VERSION ""

NS_ :

BS_:

BU_: IBCMR GW LAS AS

BO_ 1107 ACC_NM: 8 GW
 SG_ ACC_NMSourceAddress : 7|8@0+ (1,0) [0|255] ""  LAS

BO_ 1030 GW_NM: 8 GW
 SG_ GW_NMSourceAddress : 7|8@0+ (1,0) [0|255] ""  LAS

BO_ 1106 LAS_NM: 8 LAS
 SG_ LAS_NMSourceAddress : 7|8@0+ (1,0) [0|255] "" Vector__XXX

BO_ 676 ADC_2A4: 64 GW
 SG_ LCDAR_CRCCheck_2AF : 63|8@0+ (1,0) [0|255] ""  LAS
 SG_ LCDAR_RollingCounter_2AF : 51|4@0+ (1,0) [0|15] ""  LAS
 SG_ LCDAR_ELK_oAlert : 25|2@0+ (1,0) [0|3] ""  LAS
 SG_ LCDAR_ELK_oStatus : 27|2@0+ (1,0) [0|3] ""  LAS
 SG_ LCDAR_Left_ELK_oAlert : 29|2@0+ (1,0) [0|3] ""  LAS

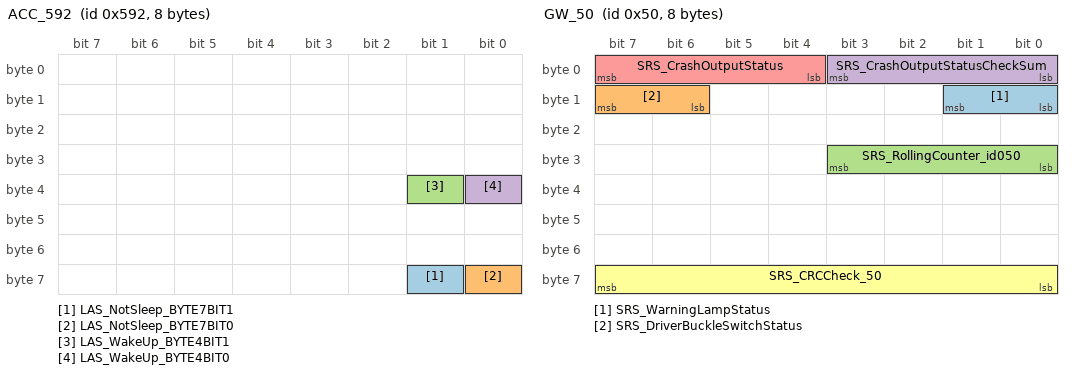
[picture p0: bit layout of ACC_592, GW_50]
BO_ 1426 ACC_592: 8 GW
 SG_ LAS_NotSleep_BYTE7BIT1 : 57|1@0+ (1,0) [0|1] ""  LAS
 SG_ LAS_NotSleep_BYTE7BIT0 : 56|1@0+ (1,0) [0|1] ""  LAS
 SG_ LAS_WakeUp_BYTE4BIT1 : 33|1@0+ (1,0) [0|1] ""  LAS
 SG_ LAS_WakeUp_BYTE4BIT0 : 32|1@0+ (1,0) [0|1] ""  LAS

BO_ 80 GW_50: 8 GW
 SG_ SRS_WarningLampStatus : 9|2@0+ (1,0) [0|3] ""  LAS
 SG_ SRS_DriverBuckleSwitchStatus : 15|2@0+ (1,0) [0|3] ""  LAS
 SG_ SRS_RollingCounter_id050 : 27|4@0+ (1,0) [0|15] ""  LAS
 SG_ SRS_CrashOutputStatusCheckSum : 3|4@0+ (1,0) [0|15] ""  LAS
 SG_ SRS_CrashOutputStatus : 7|4@0+ (1,0) [0|15] ""  LAS
 SG_ SRS_CRCCheck_50 : 63|8@0+ (1,0) [0|255] ""  LAS

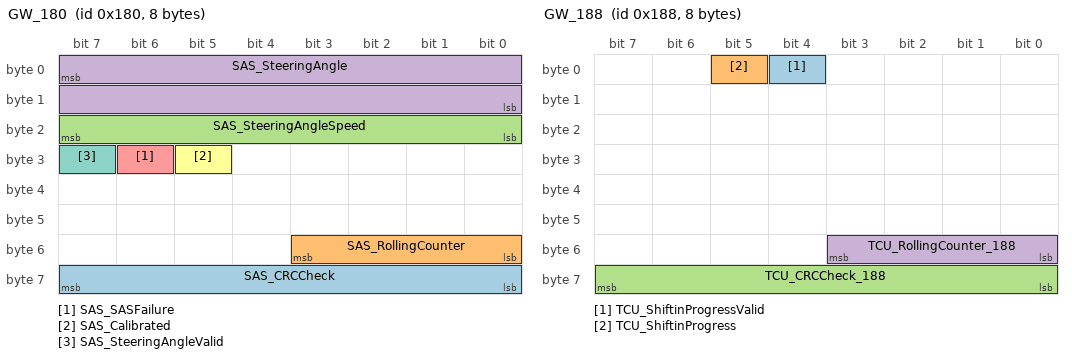
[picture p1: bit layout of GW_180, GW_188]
BO_ 384 GW_180: 8 GW
 SG_ SAS_CRCCheck : 63|8@0+ (1,0) [0|255] ""  LAS
 SG_ SAS_RollingCounter : 51|4@0+ (1,0) [0|15] ""  LAS
 SG_ SAS_SteeringAngleSpeed : 23|8@0+ (4,0) [0|1016] "deg/s"  LAS
 SG_ SAS_SteeringAngle : 7|16@0- (0.1,0) [-780|780] "degree"  LAS
 SG_ SAS_SASFailure : 30|1@0+ (1,0) [0|1] ""  LAS
 SG_ SAS_Calibrated : 29|1@0+ (1,0) [0|1] ""  LAS
 SG_ SAS_SteeringAngleValid : 31|1@0+ (1,0) [0|1] ""  LAS

BO_ 392 GW_188: 8 GW
 SG_ TCU_ShiftinProgressValid : 4|1@0+ (1,0) [0|1] ""  LAS
 SG_ TCU_ShiftinProgress : 5|1@0+ (1,0) [0|1] ""  LAS
 SG_ TCU_CRCCheck_188 : 63|8@0+ (1,0) [0|255] ""  LAS
 SG_ TCU_RollingCounter_188 : 51|4@0+ (1,0) [0|15] ""  LAS

BO_ 580 ADS_244: 64 GW
 SG_ ACC_AEBActive : 87|1@0+ (1,0) [0|1] ""  LAS

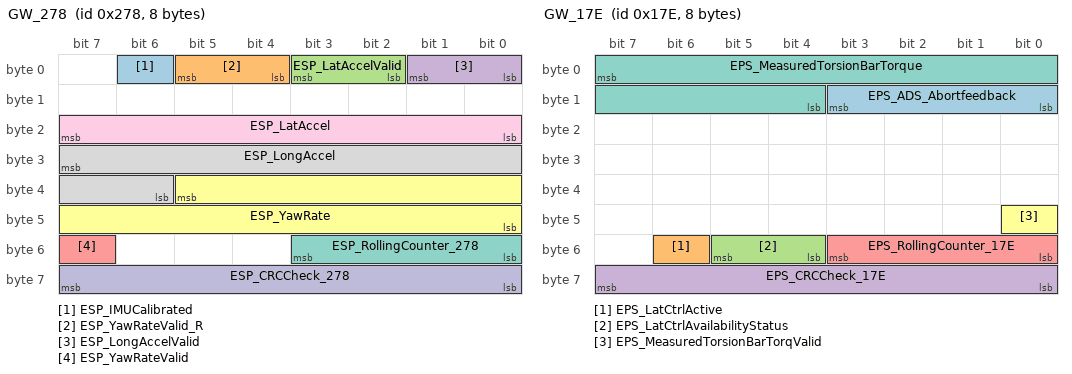
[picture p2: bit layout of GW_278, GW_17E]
BO_ 632 GW_278: 8 GW
 SG_ ESP_IMUCalibrated : 6|1@0+ (1,0) [0|1] ""  LAS
 SG_ ESP_YawRateValid_R : 5|2@0+ (1,0) [0|3] ""  LAS
 SG_ ESP_LatAccelValid : 3|2@0+ (1,0) [0|3] ""  LAS
 SG_ ESP_LongAccelValid : 1|2@0+ (1,0) [0|3] ""  LAS
 SG_ ESP_YawRateValid : 55|1@0+ (1,0) [0|1] ""  LAS
 SG_ ESP_YawRate : 37|14@0+ (0.01,-81.91) [-81.91|81.91] "degree/s"  LAS
 SG_ ESP_RollingCounter_278 : 51|4@0+ (1,0) [0|15] ""  LAS
 SG_ ESP_LongAccel : 31|10@0+ (0.03125,-16) [-16|15.90625] "m/s2"  LAS
 SG_ ESP_LatAccel : 23|8@0+ (0.1,-12.7) [-12.7|12.7] "m/s2"  LAS
 SG_ ESP_CRCCheck_278 : 63|8@0+ (1,0) [0|255] ""  LAS

BO_ 664 GW_298: 8 GW
 SG_ BCM_LeftRearDoorStatus : 40|1@0+ (1,0) [0|1] ""  LAS

BO_ 832 IBCMR_340: 8 IBCMR
 SG_ AC_FrBlowType : 2|3@0+ (1,0) [0|7] ""  LAS

BO_ 870 IBCMR_366: 8 IBCMR
 SG_ AC_EnvironmentalTemp : 23|8@0+ (0.5,-40) [-40|87] "degreeC"  LAS
 SG_ AC_EnvironmentalTempVD : 8|1@0+ (1,0) [0|1] ""  LAS

BO_ 903 GW_387: 8 GW
 SG_ BCM_RainfallLevel : 19|4@0+ (1,0) [0|15] ""  LAS
 SG_ BCM_FrontWiperStatus : 25|2@0+ (1,0) [0|3] ""  LAS

BO_ 1287 GW_507: 64 GW
 SG_ HU_FCWSetting : 165|3@0+ (1,0) [0|7] ""  LAS
 SG_ HU_IACCEnable : 29|2@0+ (1,0) [0|3] ""  LAS
 SG_ HU_LDWShakeLev : 23|2@0+ (1,0) [0|3] ""  LAS
 SG_ HU_HMAEnable : 12|1@0+ (1,0) [0|1] ""  LAS
 SG_ HU_TSRSwitch : 11|1@0+ (1,0) [0|1] ""  LAS
 SG_ HU_LASWarningModeSelection : 10|3@0+ (1,0) [0|7] ""  LAS
 SG_ HU_LASModeSelection : 5|3@0+ (1,0) [0|7] ""  LAS
 SG_ HU_OverspeedWarningOffset : 38|5@0+ (1,-10) [-10|10] ""  LAS
 SG_ HU_OverspeedWarningEnable : 33|2@0+ (1,0) [0|3] ""  LAS
 SG_ HU_OverspeedSoundWarEnable : 31|2@0+ (1,0) [0|3] ""  LAS

BO_ 1302 GW_516: 32 GW
 SG_ HU_LocalTimeSystem : 111|2@0+ (1,0) [0|3] ""  LAS
 SG_ HU_LocalTimeSecond : 109|6@0+ (1,0) [0|59] "second"  LAS
 SG_ HU_LocalTimeMinute : 101|6@0+ (1,0) [0|59] "minute"  LAS
 SG_ HU_LocalTimeHour : 92|5@0+ (1,0) [0|23] "hour"  LAS
 SG_ HU_LocalTimeDate : 84|5@0+ (1,0) [1|31] "day"  LAS
 SG_ HU_LocalTimeYear : 119|8@0+ (1,2013) [2013|2268] "year"  LAS
 SG_ HU_LocalTimeMonth : 75|4@0+ (1,0) [1|12] "month"  LAS
 SG_ HU_LocalTimeValid : 71|1@0+ (1,0) [0|1] ""  LAS
 SG_ HU_CurrentLocationLatitude : 35|28@0+ (1E-006,-134.217727) [-90|90] "degree"  LAS
 SG_ HU_CurrentLocationLongitude : 4|29@0+ (1E-006,-268.435455) [-180|180] "degree"  LAS
 SG_ HU_CurrentLocationValid : 7|1@0+ (1,0) [0|1] ""  LAS

BO_ 1328 GW_530: 8 GW
 SG_ IP_TotalOdometer : 23|24@0+ (0.1,0) [0|999999] "Km"  LAS

BO_ 378 GW_17A: 64 GW
 SG_ ESP_VehicleSpeed : 36|13@0+ (0.05625,0) [0|360] "km/h"  LAS
 SG_ ESP_VehicleSpeedValid : 37|1@0+ (1,0) [0|1] ""  LAS
 SG_ ESP_TCSFailStatus : 4|1@0+ (1,0) [0|1] ""  LAS
 SG_ ESP_RollingCounter_187 : 51|4@0+ (1,0) [0|15] ""  LAS
 SG_ ESP_ESPFunctionStatus : 1|1@0+ (1,0) [0|1] ""  LAS
 SG_ ESP_ESPActiveStatus : 0|1@0+ (1,0) [0|1] ""  LAS
 SG_ ESP_CRCCheck_197 : 127|8@0+ (1,0) [0|255] ""  LAS
 SG_ ESP_CRCCheck_187 : 63|8@0+ (1,0) [0|255] ""  LAS
 SG_ ESP_ABSFailStatus : 3|1@0+ (1,0) [0|1] ""  LAS
 SG_ ESP_ABSActiveStatus : 7|1@0+ (1,0) [0|1] ""  LAS

BO_ 382 GW_17E: 8 GW
 SG_ EPS_ADS_Abortfeedback : 11|4@0+ (1,0) [0|15] ""  LAS
 SG_ EPS_LatCtrlActive : 54|1@0+ (1,0) [0|1] ""  LAS
 SG_ EPS_LatCtrlAvailabilityStatus : 53|2@0+ (1,0) [0|3] ""  LAS
 SG_ EPS_CRCCheck_17E : 63|8@0+ (1,0) [0|255] ""  LAS
 SG_ EPS_RollingCounter_17E : 51|4@0+ (1,0) [0|15] ""  LAS
 SG_ EPS_MeasuredTorsionBarTorqValid : 40|1@0+ (1,0) [0|1] ""  LAS
 SG_ EPS_MeasuredTorsionBarTorque : 7|12@0+ (0.01,-20.48) [-20.48|20.46] "Nm"  LAS

BO_ 398 GW_18E: 32 GW
 SG_ EMS_CRCCheck_1A6 : 191|8@0+ (1,0) [0|255] ""  LAS
 SG_ EMS_RollingCounter_1A6 : 179|4@0+ (1,0) [0|15] ""  LAS
 SG_ EMS_EngineStatus : 183|2@0+ (1,0) [0|3] ""  LAS
 SG_ EMS_AccPedal : 111|8@0+ (0.392,0) [0|99.568] "%"  LAS
 SG_ EMS_EngineSpeed : 87|16@0+ (0.25,0) [0|16383.5] "Rpm"  LAS
 SG_ EMS_BrakePedalStatus : 119|2@0+ (1,0) [0|3] ""  LAS
 SG_ EMS_RealAccPedal : 71|8@0+ (0.392,0) [0|99.568] "%"  LAS

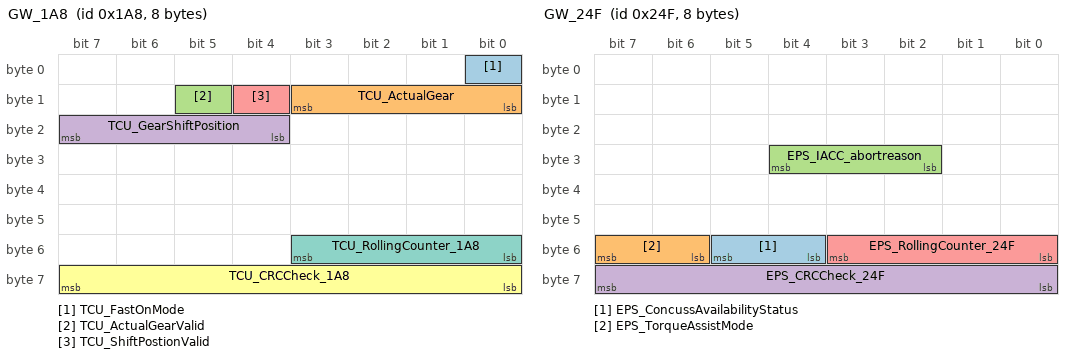
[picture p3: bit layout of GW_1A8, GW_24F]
BO_ 424 GW_1A8: 8 GW
 SG_ TCU_FastOnMode : 0|1@0+ (1,0) [0|1] ""  LAS
 SG_ TCU_ActualGear : 11|4@0+ (1,0) [0|15] ""  LAS
 SG_ TCU_ActualGearValid : 13|1@0+ (1,0) [0|1] ""  LAS
 SG_ TCU_GearShiftPosition : 23|4@0+ (1,0) [0|15] ""  LAS
 SG_ TCU_ShiftPostionValid : 12|1@0+ (1,0) [0|1] ""  LAS
 SG_ TCU_CRCCheck_1A8 : 63|8@0+ (1,0) [0|255] ""  LAS
 SG_ TCU_RollingCounter_1A8 : 51|4@0+ (1,0) [0|15] ""  LAS

BO_ 523 EPBi_20B: 64 GW
 SG_ Wheel_Speed_FL_Pulse : 135|8@0+ (1,0) [0|254] ""  LAS
 SG_ Wheel_Speed_FR_Pulse : 159|8@0+ (1,0) [0|254] ""  LAS
 SG_ ESP_Vehicle_Speed_Reference : 103|13@0+ (0.05625,0) [0|360] "km/h"  LAS
 SG_ Wheel_Speed_RR_Valid_Data : 71|1@0+ (1,0) [0|1] ""  LAS
 SG_ Wheel_Speed_RR_Pulse : 231|8@0+ (1,0) [0|254] ""  LAS
 SG_ Wheel_Speed_RR_Direction : 70|2@0+ (1,0) [0|3] ""  LAS
 SG_ Wheel_Speed_RR_Data : 68|13@0+ (0.05625,0) [0|360] "km/h"  LAS
 SG_ Wheel_Speed_RL_Valid_Data : 87|1@0+ (1,0) [0|1] ""  LAS
 SG_ Wheel_Speed_RL_Pulse : 239|8@0+ (1,0) [0|254] ""  LAS
 SG_ Wheel_Speed_RL_Direction : 86|2@0+ (1,0) [0|3] ""  LAS
 SG_ Wheel_Speed_RL_Data : 84|13@0+ (0.05625,0) [0|360] "km/h"  LAS
 SG_ Wheel_Speed_FR_Valid_Data : 7|1@0+ (1,0) [0|1] ""  LAS
 SG_ Wheel_Speed_FR_Pulse : 223|8@0+ (1,0) [0|254] ""  LAS
 SG_ Wheel_Speed_FR_Direction : 6|2@0+ (1,0) [0|3] ""  LAS
 SG_ Wheel_Speed_FR_Data : 4|13@0+ (0.05625,0) [0|360] "km/h"  LAS
 SG_ Wheel_Speed_FL_Valid_Data : 23|1@0+ (1,0) [0|1] ""  LAS
 SG_ Wheel_Speed_FL_Pulse : 215|8@0+ (1,0) [0|254] ""  LAS
 SG_ Wheel_Speed_FL_Direction : 22|2@0+ (1,0) [0|3] ""  LAS
 SG_ Wheel_Speed_FL_Data : 20|13@0+ (0.05625,0) [0|360] "km/h"  LAS
 SG_ ESP_VehicleStandstill : 267|1@0+ (1,0) [0|1] ""  LAS
 SG_ ESP_VDCActive : 266|1@0+ (1,0) [0|1] ""  LAS
 SG_ ESP_TCSActive : 265|1@0+ (1,0) [0|1] ""  LAS
 SG_ ESP_RollingCounter_277 : 307|4@0+ (1,0) [0|15] ""  LAS
 SG_ ESP_RollingCounter_258 : 243|4@0+ (1,0) [0|15] ""  LAS
 SG_ ESP_RollingCounter_208 : 115|4@0+ (1,0) [0|15] ""  LAS
 SG_ ESP_RollingCounter_206 : 51|4@0+ (1,0) [0|15] ""  LAS
 SG_ ESP_PrefillAvailable : 259|1@0+ (1,0) [0|1] ""  LAS
 SG_ ESP_PrefillActive : 260|1@0+ (1,0) [0|1] ""  LAS
 SG_ ESP_OnlyABSActive : 264|1@0+ (1,0) [0|1] ""  LAS
 SG_ ESP_MasCylBrakePressureValid : 199|1@0+ (1,0) [0|1] ""  LAS
 SG_ ESP_MasCylBrakePressure : 195|12@0+ (0.1,0) [0|250] "Bar"  LAS
 SG_ ESP_CRCCheck_277 : 319|8@0+ (1,0) [0|255] ""  LAS
 SG_ ESP_CRCCheck_258 : 255|8@0+ (1,0) [0|255] ""  LAS
 SG_ ESP_CRCCheck_208 : 127|8@0+ (1,0) [0|255] ""  LAS
 SG_ ESP_CRCCheck_206 : 63|8@0+ (1,0) [0|255] ""  LAS
 SG_ ESP_BrakeForce : 263|1@0+ (1,0) [0|1] ""  LAS
 SG_ ESP_AWBavailable : 271|1@0+ (1,0) [0|1] ""  LAS
 SG_ ESP_AWBactive : 256|1@0+ (1,0) [0|1] ""  LAS
 SG_ ESP_AEBdecActive : 257|1@0+ (1,0) [0|1] ""  LAS
 SG_ ESP_AEBAvailable : 258|1@0+ (1,0) [0|1] ""  LAS
 SG_ ESP_ABAavailable : 261|1@0+ (1,0) [0|1] ""  LAS
 SG_ ESP_ABAactive : 262|1@0+ (1,0) [0|1] ""  LAS

BO_ 591 GW_24F: 8 GW
 SG_ EPS_ConcussAvailabilityStatus : 53|2@0+ (1,0) [0|3] ""  LAS
 SG_ EPS_TorqueAssistMode : 55|2@0+ (1,0) [0|3] ""  LAS
 SG_ EPS_IACC_abortreason : 28|3@0+ (1,0) [0|7] ""  LAS
 SG_ EPS_CRCCheck_24F : 63|8@0+ (1,0) [0|255] ""  LAS
 SG_ EPS_RollingCounter_24F : 51|4@0+ (1,0) [0|15] ""  LAS

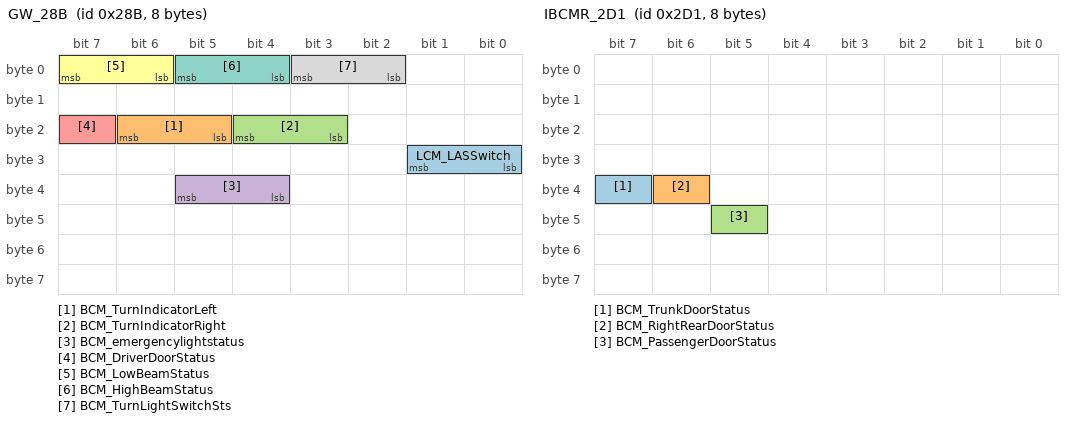
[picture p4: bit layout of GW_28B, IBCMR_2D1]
BO_ 651 GW_28B: 8 GW
 SG_ LCM_LASSwitch : 25|2@0+ (1,0) [0|3] ""  LAS
 SG_ BCM_TurnIndicatorLeft : 22|2@0+ (1,0) [0|3] ""  LAS
 SG_ BCM_TurnIndicatorRight : 20|2@0+ (1,0) [0|3] ""  LAS
 SG_ BCM_emergencylightstatus : 37|2@0+ (1,0) [0|3] ""  LAS
 SG_ BCM_DriverDoorStatus : 23|1@0+ (1,0) [0|1] ""  LAS
 SG_ BCM_LowBeamStatus : 7|2@0+ (1,0) [0|3] ""  LAS
 SG_ BCM_HighBeamStatus : 5|2@0+ (1,0) [0|3] ""  LAS
 SG_ BCM_TurnLightSwitchSts : 3|2@0+ (1,0) [0|3] ""  LAS

BO_ 721 IBCMR_2D1: 8 IBCMR
 SG_ BCM_TrunkDoorStatus : 39|1@0+ (1,0) [0|1] ""  LAS
 SG_ BCM_RightRearDoorStatus : 38|1@0+ (1,0) [0|1] ""  LAS
 SG_ BCM_PassengerDoorStatus : 45|1@0+ (1,0) [0|1] ""  LAS

BO_ 943 GW_3AF: 64 GW
 SG_ HU_CRCCheck_3AF : 255|8@0+ (1,0) [0|255] ""  LAS
 SG_ HU_RollingCounter_3AF : 243|4@0+ (1,0) [0|15] ""  LAS
 SG_ HU_RampDistance : 239|10@0+ (10,0) [0|3000] "m"  LAS
 SG_ HU_NavSpeedLimitType : 231|2@0+ (1,0) [0|3] ""  LAS
 SG_ HU_CurveDistance : 229|6@0+ (10,0) [0|600] "m"  LAS
 SG_ HU_EnterCurveInfo : 220|2@0+ (1,0) [0|3] ""  LAS
 SG_ HU_NavCurrentRoadType : 218|3@0+ (1,0) [0|7] ""  LAS
 SG_ HU_EnterRampInfo : 215|2@0+ (1,0) [0|3] ""  LAS
 SG_ HU_RampInfo : 209|2@0+ (1,0) [0|3] ""  LAS
 SG_ HU_NavCountryCode : 199|8@0+ (1,0) [0|255] ""  LAS
 SG_ HU_NavStatus : 223|1@0+ (1,0) [0|1] ""  LAS
 SG_ HU_NavSpeedLimitUnits : 213|2@0+ (1,0) [0|3] ""  LAS
 SG_ HU_NavSpeedLimitStatus : 211|2@0+ (1,0) [0|3] ""  LAS
 SG_ HU_NavSpeedLimit : 207|8@0+ (1,0) [0|255] ""  LAS

BO_ 947 IBCMR_3B3: 8 IBCMR
 SG_ BCM_RearFoglampStatus : 19|2@0+ (1,0) [0|3] ""  LAS

BO_ 957 GW_3BD: 64 GW
 SG_ HU_ELKEnable : 1|2@0+ (1,0) [0|3] ""  LAS
 SG_ HU_TLAEnable : 9|2@0+ (1,0) [0|3] ""  LAS

BO_ 964 GW_3C4: 64 GW
 SG_ HU_CRCCheck_3C7 : 319|8@0+ (1,0) [0|255] ""  LAS
 SG_ HU_RollingCounter_3C7 : 307|4@0+ (1,0) [0|15] ""  LAS
 SG_ HU_CRCCheck_3C6 : 255|8@0+ (1,0) [0|255] ""  LAS
 SG_ HU_RollingCounter_3C6 : 243|4@0+ (1,0) [0|15] ""  LAS
 SG_ HU_CRCCheck_3C4 : 191|8@0+ (1,0) [0|255] ""  LAS
 SG_ HU_RollingCounter_3C4 : 179|4@0+ (1,0) [0|15] ""  LAS
 SG_ HU_CRCCheck_3C2 : 127|8@0+ (1,0) [0|255] ""  LAS
 SG_ HU_RollingCounter_3C2 : 115|4@0+ (1,0) [0|15] ""  LAS
 SG_ HU_MapMatchStatus : 309|2@0+ (1,0) [0|3] ""  LAS
 SG_ HU_MapDataUpdateStatus : 118|3@0+ (1,0) [0|7] ""  LAS
 SG_ HU_SlopeGradient_300m : 303|10@0+ (0.1,-51.1) [-51.1|51.1] "%"  LAS
 SG_ HU_RoadCurvature_600m : 281|10@0+ (1,0) [0|1023] "1/m"  LAS
 SG_ HU_RoadCurvature_400m : 275|10@0+ (1,0) [0|1023] "1/m"  LAS
 SG_ HU_RoadCurvature_300m : 269|10@0+ (1,0) [0|1023] "1/m"  LAS
 SG_ HU_RoadCurvature_100m : 263|10@0+ (1,0) [0|1023] "1/m"  LAS
 SG_ HU_RoadCurvature_90m : 239|10@0+ (1,0) [0|1023] "1/m"  LAS
 SG_ HU_RoadCurvature_80m : 217|10@0+ (1,0) [0|1023] "1/m"  LAS
 SG_ HU_RoadCurvature_70m : 211|10@0+ (1,0) [0|1023] "1/m"  LAS
 SG_ HU_RoadCurvature_60m : 205|10@0+ (1,0) [0|1023] "1/m"  LAS
 SG_ HU_RoadCurvature_50m : 199|10@0+ (1,0) [0|1023] "1/m"  LAS
 SG_ HU_RoadCurvature_40m : 161|10@0+ (1,0) [0|1023] "1/m"  LAS
 SG_ HU_RoadCurvature_30m : 155|10@0+ (1,0) [0|1023] "1/m"  LAS
 SG_ HU_RoadCurvature_20m : 149|10@0+ (1,0) [0|1023] "1/m"  LAS
 SG_ HU_RoadCurvature_10m : 143|10@0+ (1,0) [0|1023] "1/m"  LAS
 SG_ HU_Road_TrafficFlow : 105|3@0+ (1,0) [0|7] ""  LAS
 SG_ HU_Lane_Changtype : 129|2@0+ (1,0) [0|3] ""  LAS
 SG_ HU_To_NumchangeOfLanes_Dist : 135|6@0+ (10,0) [0|600] "m"  LAS
 SG_ HU_To_Branch_Dis : 111|6@0+ (10,0) [0|600] "m"  LAS
 SG_ HU_BranchInfo : 245|2@0+ (1,0) [0|3] ""  LAS
 SG_ HU_To_TrafficAccident_Dis : 101|6@0+ (10,0) [0|600] "m"  LAS
 SG_ HU_TrafficAccident_Info : 103|2@0+ (1,0) [0|3] ""  LAS
 SG_ HU_To_Construction_Dis : 93|6@0+ (10,0) [0|600] "m"  LAS
 SG_ HU_Construction_Info : 95|2@0+ (1,0) [0|3] ""  LAS
 SG_ HU_TollDis : 85|6@0+ (10,0) [0|600] "m"  LAS
 SG_ HU_TollInfo : 87|2@0+ (1,0) [0|3] ""  LAS
 SG_ HU_FallingRockDi : 77|6@0+ (10,0) [0|600] "m"  LAS
 SG_ HU_FallingRockInfo : 79|2@0+ (1,0) [0|3] ""  LAS
 SG_ HU_LaneCnt : 66|3@0+ (1,0) [0|7] ""  LAS
 SG_ HU_ForwardRoadType : 69|3@0+ (1,0) [0|7] ""  LAS
 SG_ HU_RampSide : 71|2@0+ (1,0) [0|3] ""  LAS
 SG_ HU_CRCCheck_3B8 : 63|8@0+ (1,0) [0|255] ""  LAS
 SG_ HU_RollingCounter_3B8 : 51|4@0+ (1,0) [0|15] ""  LAS
 SG_ HU_NavGuiganceStatus : 47|2@0+ (1,0) [0|3] ""  LAS
 SG_ HU_SlopeDistance : 45|6@0+ (10,0) [0|600] "m"  LAS
 SG_ HU_Byroad : 39|2@0+ (1,0) [0|3] ""  LAS
 SG_ HU_TunnelLength : 37|6@0+ (1,0) [0|63] "m"  LAS
 SG_ HU_RoadCurvatureFar : 17|10@0+ (1,0) [0|1023] ""  LAS
 SG_ HU_TunnelDistance : 23|6@0+ (10,0) [0|600] "m"  LAS
 SG_ HU_RoadCurvature : 1|10@0+ (1,0) [0|1023] ""  LAS
 SG_ HU_EnterSlopeInfo : 5|2@0+ (1,0) [0|3] ""  LAS
 SG_ HU_EnterTunnelInfo : 3|2@0+ (1,0) [0|3] ""  LAS

BO_ 1021 GW_3FD: 8 GW
 SG_ BCM_PowerManageLevel : 8|3@0+ (1,0) [0|7] ""  LAS

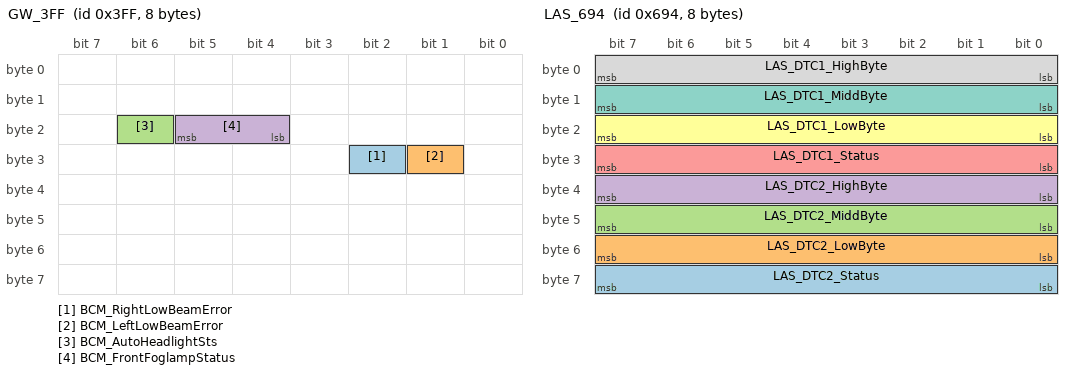
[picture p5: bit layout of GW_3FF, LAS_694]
BO_ 1023 GW_3FF: 8 GW
 SG_ BCM_RightLowBeamError : 26|1@0+ (1,0) [0|1] ""  LAS
 SG_ BCM_LeftLowBeamError : 25|1@0+ (1,0) [0|1] ""  LAS
 SG_ BCM_AutoHeadlightSts : 22|1@0+ (1,0) [0|1] ""  LAS
 SG_ BCM_FrontFoglampStatus : 21|2@0+ (1,0) [0|3] ""  LAS

BO_ 1684 LAS_694: 8 LAS
 SG_ LAS_DTC2_Status : 63|8@0+ (1,0) [0|255] "" Vector__XXX
 SG_ LAS_DTC2_LowByte : 55|8@0+ (1,0) [0|255] "" Vector__XXX
 SG_ LAS_DTC2_MiddByte : 47|8@0+ (1,0) [0|255] "" Vector__XXX
 SG_ LAS_DTC2_HighByte : 39|8@0+ (1,0) [0|255] "" Vector__XXX
 SG_ LAS_DTC1_Status : 31|8@0+ (1,0) [0|255] "" Vector__XXX
 SG_ LAS_DTC1_LowByte : 23|8@0+ (1,0) [0|255] "" Vector__XXX
 SG_ LAS_DTC1_MiddByte : 15|8@0+ (1,0) [0|255] "" Vector__XXX
 SG_ LAS_DTC1_HighByte : 7|8@0+ (1,0) [0|255] "" Vector__XXX

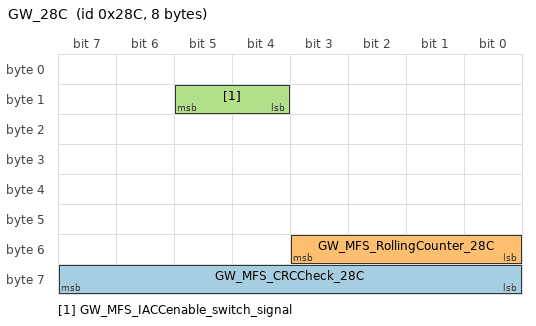
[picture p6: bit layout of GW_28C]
BO_ 652 GW_28C: 8 GW
 SG_ GW_MFS_CRCCheck_28C : 63|8@0+ (1,0) [0|255] ""  LAS
 SG_ GW_MFS_RollingCounter_28C : 51|4@0+ (1,0) [0|15] ""  LAS
 SG_ GW_MFS_IACCenable_switch_signal : 13|2@0+ (1,0) [0|3] ""  LAS

BO_ 800 GW_320: 8 GW
 SG_ GW_ResetReq : 31|7@0+ (1,0) [0|127] ""  LAS

BO_ 922 LAS_39A: 64 LAS
 SG_ LAS_ResetSts : 263|3@0+ (1,0) [0|7] "" Vector__XXX
 SG_ ACC_RollingCounter_39A : 491|4@0+ (1,0) [0|15] "" Vector__XXX
 SG_ ACC_CRCCheck_39A : 503|16@0+ (1,0) [0|65535] "" Vector__XXX
 SG_ LAS_TSRRightLaneStatus : 55|3@0+ (1,0) [0|7] "" Vector__XXX
 SG_ LAS_TSRLeftLaneStatus : 47|3@0+ (1,0) [0|7] "" Vector__XXX
 SG_ LAS_CRCCheck_3C0 : 191|8@0+ (1,0) [0|255] "" Vector__XXX
 SG_ LAS_RollingCounter_3C0 : 179|4@0+ (1,0) [0|15] "" Vector__XXX
 SG_ LAS_TSRRightLaneSpdLimit : 143|8@0+ (1,0) [0|255] "" Vector__XXX
 SG_ LAS_TSRLeftLaneSpdLimit : 135|8@0+ (1,0) [0|255] "" Vector__XXX
 SG_ LAS_CRCCheck_3D4 : 127|8@0+ (1,0) [0|255] "" Vector__XXX
 SG_ LAS_RollingCounter_3D4 : 115|4@0+ (1,0) [0|15] "" Vector__XXX
 SG_ LAS_TLAStopLine_HostLane : 111|8@0+ (1,0) [0|255] "" Vector__XXX
 SG_ LAS_TLADistance_HostLane : 103|8@0+ (1,0) [0|255] "" Vector__XXX
 SG_ LAS_TLACountDownTime_HostLane : 94|7@0+ (1,0) [0|127] "" Vector__XXX
 SG_ LAS_TSRMandatorySign : 70|4@0+ (1,0) [0|15] "" Vector__XXX
 SG_ LAS_TSRWarningSign : 83|4@0+ (1,0) [0|15] "" Vector__XXX
 SG_ LAS_TSRProhibitionSign : 66|5@0+ (1,0) [0|31] "" Vector__XXX
 SG_ LAS_CRCCheck_332 : 63|8@0+ (1,0) [0|255] "" Vector__XXX
 SG_ LAS_RollingCounter_332 : 51|4@0+ (1,0) [0|15] "" Vector__XXX
 SG_ LAS_OverspeedSoundWarningEnSt : 27|1@0+ (1,0) [0|1] "" Vector__XXX
 SG_ LAS_TSREnable : 30|1@0+ (1,0) [0|1] "" Vector__XXX
 SG_ LAS_HMAEnableStatus : 22|1@0+ (1,0) [0|1] "" Vector__XXX
 SG_ LAS_HMALightDistribution : 8|1@0+ (1,0) [0|1] "" Vector__XXX
 SG_ LAS_HMAStatus : 44|2@0+ (1,0) [0|3] "" Vector__XXX
 SG_ LAS_TSRHostSpdLimitUnits : 41|2@0+ (1,0) [0|3] "" Vector__XXX
 SG_ LAS_TSRHostSpdLimit : 39|8@0+ (1,0) [0|255] "" Vector__XXX
 SG_ LAS_TSRStatus : 26|3@0+ (1,0) [0|7] "" Vector__XXX
 SG_ LAS_FrontCameraCalibrationStatus : 20|2@0+ (1,0) [0|3] "" Vector__XXX
 SG_ LAS_FrontCameraFailureStatus : 17|2@0+ (1,0) [0|3] "" Vector__XXX
 SG_ LAS_OverspeedWarningOffset : 14|5@0+ (1,-10) [-10|10] "km/h" Vector__XXX
 SG_ LAS_OverspeedWarningEnableStatus : 15|1@0+ (1,0) [0|1] "" Vector__XXX
 SG_ LAS_OverspeedSoundWarning : 2|1@0+ (1,0) [0|1] "" Vector__XXX
 SG_ LAS_OverspeedVisualWarning : 5|1@0+ (1,0) [0|1] "" Vector__XXX
 SG_ LAS_CRCCheck_37D : 255|8@0+ (1,0) [0|255] "" Vector__XXX
 SG_ LAS_RollingCounter_37D : 243|4@0+ (1,0) [0|15] "" Vector__XXX
 SG_ LAS_TLAArrowDirection_RightLane : 236|3@0+ (1,0) [0|7] "" Vector__XXX
 SG_ LAS_TLAObjectType_RightLane : 239|3@0+ (1,0) [0|7] "" Vector__XXX
 SG_ LAS_TLAObjectStatus_RightLane : 247|2@0+ (1,0) [0|3] "" Vector__XXX
 SG_ LAS_TLAObjectColour_RightLane : 225|2@0+ (1,0) [0|3] "" Vector__XXX
 SG_ LAS_TLAObjectDetection_RightLane : 227|1@0+ (1,0) [0|1] "" Vector__XXX
 SG_ LAS_TLAArrowDirection_LeftLane : 216|3@0+ (1,0) [0|7] "" Vector__XXX
 SG_ LAS_TLAObjectType_LeftLane : 219|3@0+ (1,0) [0|7] "" Vector__XXX
 SG_ LAS_TLAObjectStatus_LeftLane : 245|2@0+ (1,0) [0|3] "" Vector__XXX
 SG_ LAS_TLAObjectColour_LeftLane : 221|2@0+ (1,0) [0|3] "" Vector__XXX
 SG_ LAS_TLAObjectDetection_LeftLane : 223|1@0+ (1,0) [0|1] "" Vector__XXX
 SG_ LAS_TLAArrowDirection_HostLane : 215|3@0+ (1,0) [0|7] "" Vector__XXX
 SG_ LAS_TLAObjectStatus_HostLane : 199|2@0+ (1,0) [0|3] "" Vector__XXX
 SG_ LAS_TLAObjectType_HostLane : 212|3@0+ (1,0) [0|7] "" Vector__XXX
 SG_ LAS_TLAObjectColour_HostLane : 204|2@0+ (1,0) [0|3] "" Vector__XXX
 SG_ LAS_TLAObjectDetection_HostLane : 200|1@0+ (1,0) [0|1] "" Vector__XXX
 SG_ LAS_TLAWarninglevel : 197|2@0+ (1,0) [0|3] "" Vector__XXX
 SG_ LAS_TLAStatus : 193|2@0+ (1,0) [0|3] "" Vector__XXX
 SG_ LAS_TLAEnable : 194|1@0+ (1,0) [0|1] "" Vector__XXX

BO_ 1000 GW_3E8: 8 GW
 SG_ BCM_SOF_Q_STATE : 51|2@0+ (1,0) [0|3] ""  LAS
 SG_ BCM_SOF_Q : 15|8@0+ (0.5,0) [0|127] "Ah"  LAS

BO_ 999 GW_3E7: 8 GW
 SG_ BCM_Status_Temp : 51|2@0+ (1,0) [0|3] ""  LAS
 SG_ BCM_T_BATT : 39|8@0+ (1,-40) [-40|105] "C"  LAS

BO_ 583 APA_247: 32 GW
 SG_ APA_APAOnOff : 6|1@0+ (1,0) [0|1] ""  LAS

BO_ 738 GW_2E2: 64 GW
 SG_ RLR_CRCCheck_2E2 : 503|16@0+ (1,0) [0|65535] ""  LAS
 SG_ RLR_RollingCounter_2E2 : 491|4@0+ (1,0) [0|15] ""  LAS
 SG_ RLR_ElkOBJ2_Measured : 313|2@0+ (1,0) [0|3] ""  LAS
 SG_ RLR_ElkOBJ2_ExistProb : 319|6@0+ (2,0) [0|100] "%"  LAS
 SG_ RLR_ElkOBJ2_Location : 305|2@0+ (1,0) [0|3] ""  LAS
 SG_ RLR_ElkOBJ2_RelAx : 298|9@0+ (0.0625,-16) [-16|15.9375] "m/s2"  LAS
 SG_ RLR_ElkOBJ2_RelAy : 292|10@0+ (0.03125,-16) [-16|15.9688] "m/s2"  LAS
 SG_ RLR_ElkOBJ2_RelVx : 272|12@0+ (0.0625,-128) [-128|127.938] "m/s"  LAS
 SG_ RLR_ElkOBJ2_RelVy : 266|10@0+ (0.125,-64) [-64|63.875] "m/s"  LAS
 SG_ RLR_ElkOBJ2_Dx : 263|13@0+ (0.0625,-256) [-256|255.938] "m"  LAS
 SG_ RLR_ElkOBJ2_RefPointLoc : 251|3@0+ (1,0) [0|7] ""  LAS
 SG_ RLR_ElkOBJ2_Dy : 246|11@0+ (0.125,-128) [-128|127.875] "m"  LAS
 SG_ RLR_ElkOBJ2_HeadingAngle : 224|10@0+ (0.01,-3.14) [-3.14|3.14] "rad"  LAS
 SG_ RLR_ElkOBJ2_Length : 217|9@0+ (0.05,0) [0|25.5] "m"  LAS
 SG_ RLR_ElkOBJ2_Height : 210|9@0+ (0.01,0) [0|5.11] "m"  LAS
 SG_ RLR_ElkOBJ2_Width : 205|11@0+ (0.01,0) [0|12] "m"  LAS
 SG_ RLR_ElkOBJ2_Type : 192|3@0+ (1,0) [0|7] ""  LAS
 SG_ RLR_ElkOBJ2_Track_ID : 199|7@0+ (1,0) [0|127] ""  LAS
 SG_ RLR_ElkOBJ2_RefPointDx : 168|13@0+ (0.0625,-256) [-256|255.938] "m"  LAS,AS
 SG_ RLR_ElkOBJ2_RefPointDy : 163|11@0+ (0.125,-128) [-128|127.875] "m"  LAS
 SG_ RLR_ElkOBJ2_ObstacleProb : 153|6@0+ (2,0) [0|100] "%"  LAS
 SG_ RLR_ElkOBJ1_RefPointDx : 150|13@0+ (0.0625,-256) [-256|255.938] "m"  LAS,AS
 SG_ RLR_ElkOBJ1_RefPointDy : 129|11@0+ (0.125,-128) [-128|127.875] "m"  LAS
 SG_ RLR_ElkOBJ1_ObstacleProb : 135|6@0+ (2,0) [0|100] "%"  LAS
 SG_ RLR_ElkOBJ1_Measured : 121|2@0+ (1,0) [0|3] ""  LAS
 SG_ RLR_ElkOBJ1_ExistProb : 127|6@0+ (2,0) [0|100] "%"  LAS
 SG_ RLR_ElkOBJ1_Location : 113|2@0+ (1,0) [0|3] ""  LAS
 SG_ RLR_ElkOBJ1_RelAx : 106|9@0+ (0.0625,-16) [-16|15.9375] "m/s2"  LAS
 SG_ RLR_ElkOBJ1_RelAy : 100|10@0+ (0.03125,-16) [-16|15.9688] "m/s2"  LAS
 SG_ RLR_ElkOBJ1_RelVx : 80|12@0+ (0.0625,-128) [-128|127.938] "m/s"  LAS
 SG_ RLR_ElkOBJ1_RelVy : 327|10@0+ (0.125,-64) [-64|63.875] "m/s"  LAS
 SG_ RLR_ElkOBJ1_Dx : 71|13@0+ (0.0625,-256) [-256|255.938] "m"  LAS
 SG_ RLR_ElkOBJ1_RefPointLoc : 59|3@0+ (1,0) [0|7] ""  LAS
 SG_ RLR_ElkOBJ1_Dy : 54|11@0+ (0.125,-128) [-128|127.875] "m"  LAS
 SG_ RLR_ElkOBJ1_HeadingAngle : 32|10@0+ (0.01,-3.14) [-3.14|3.14] "rad"  LAS,AS
 SG_ RLR_ElkOBJ1_Length : 25|9@0+ (0.05,0) [0|25.55] "m"  LAS
 SG_ RLR_ElkOBJ1_Height : 18|9@0+ (0.01,0) [0|5.11] "m"  LAS
 SG_ RLR_ElkOBJ1_Width : 13|11@0+ (0.01,0) [0|12] "m"  LAS
 SG_ RLR_ElkOBJ1_Type : 0|3@0+ (1,0) [0|7] ""  LAS
 SG_ RLR_ElkOBJ1_Track_ID : 7|7@0+ (1,0) [0|127] ""  LAS

BO_ 739 GW_2E3: 64 GW
 SG_ RLR_CRCCheck_2E3 : 503|16@0+ (1,0) [0|65535] ""  LAS
 SG_ RLR_RollingCounter_2E3 : 491|4@0+ (1,0) [0|15] ""  LAS
 SG_ RLR_ElkOBJ4_Measured : 313|2@0+ (1,0) [0|3] ""  LAS
 SG_ RLR_ElkOBJ4_ExistProb : 319|6@0+ (2,0) [0|100] "%"  LAS
 SG_ RLR_ElkOBJ4_Location : 305|2@0+ (1,0) [0|3] ""  LAS
 SG_ RLR_ElkOBJ4_RelAx : 298|9@0+ (0.0625,-16) [-16|15.9375] "m/s2"  LAS
 SG_ RLR_ElkOBJ4_RelAy : 292|10@0+ (0.03125,-16) [-16|15.9688] "m/s2"  LAS
 SG_ RLR_ElkOBJ4_RelVx : 272|12@0+ (0.0625,-128) [-128|127.938] "m/s"  LAS
 SG_ RLR_ElkOBJ4_RelVy : 266|10@0+ (0.125,-64) [-64|63.875] "m/s"  LAS
 SG_ RLR_ElkOBJ4_Dx : 263|13@0+ (0.0625,-256) [-256|255.938] "m"  LAS
 SG_ RLR_ElkOBJ4_RefPointLoc : 251|3@0+ (1,0) [0|7] ""  LAS
 SG_ RLR_ElkOBJ4_Dy : 246|11@0+ (0.125,-128) [-128|127.875] "m"  LAS
 SG_ RLR_ElkOBJ4_HeadingAngle : 224|10@0+ (0.01,-3.14) [-3.14|3.14] "rad"  LAS
 SG_ RLR_ElkOBJ4_Length : 217|9@0+ (0.05,0) [0|25.5] "m"  LAS
 SG_ RLR_ElkOBJ4_Height : 210|9@0+ (0.01,0) [0|5.11] "m"  LAS
 SG_ RLR_ElkOBJ4_Width : 205|11@0+ (0.01,0) [0|12] "m"  LAS
 SG_ RLR_ElkOBJ4_Type : 192|3@0+ (1,0) [0|7] ""  LAS
 SG_ RLR_ElkOBJ4_Track_ID : 199|7@0+ (1,0) [0|127] ""  LAS
 SG_ RLR_ElkOBJ4_RefPointDx : 168|13@0+ (0.0625,-256) [-256|255.938] "m"  LAS,AS
 SG_ RLR_ElkOBJ4_RefPointDy : 163|11@0+ (0.125,-128) [-128|127.875] "m"  LAS
 SG_ RLR_ElkOBJ4_ObstacleProb : 153|6@0+ (2,0) [0|100] "%"  LAS
 SG_ RLR_ElkOBJ3_RefPointDx : 150|13@0+ (0.0625,-256) [-256|255.938] "m"  LAS,AS
 SG_ RLR_ElkOBJ3_RefPointDy : 129|11@0+ (0.125,-128) [-128|127.875] "m"  LAS
 SG_ RLR_ElkOBJ3_ObstacleProb : 135|6@0+ (2,0) [0|100] "%"  LAS
 SG_ RLR_ElkOBJ3_Measured : 121|2@0+ (1,0) [0|3] ""  LAS
 SG_ RLR_ElkOBJ3_ExistProb : 127|6@0+ (2,0) [0|100] "%"  LAS
 SG_ RLR_ElkOBJ3_Location : 113|2@0+ (1,0) [0|3] ""  LAS
 SG_ RLR_ElkOBJ3_RelAx : 106|9@0+ (0.0625,-16) [-16|15.9375] "m/s2"  LAS
 SG_ RLR_ElkOBJ3_RelAy : 100|10@0+ (0.03125,-16) [-16|15.9688] "m/s2"  LAS
 SG_ RLR_ElkOBJ3_RelVx : 80|12@0+ (0.0625,-128) [-128|127.938] "m/s"  LAS
 SG_ RLR_ElkOBJ3_RelVy : 74|10@0+ (0.125,-64) [-64|63.875] "m/s"  LAS
 SG_ RLR_ElkOBJ3_Dx : 71|13@0+ (0.0625,-256) [-256|255.938] "m"  LAS
 SG_ RLR_ElkOBJ3_RefPointLoc : 59|3@0+ (1,0) [0|7] ""  LAS
 SG_ RLR_ElkOBJ3_Dy : 54|11@0+ (0.125,-128) [-128|127.875] "m"  LAS
 SG_ RLR_ElkOBJ3_HeadingAngle : 32|10@0+ (0.01,-3.14) [-3.14|3.14] "rad"  LAS,AS
 SG_ RLR_ElkOBJ3_Length : 25|9@0+ (0.05,0) [0|25.5] "m"  LAS
 SG_ RLR_ElkOBJ3_Height : 18|9@0+ (0.01,0) [0|5.11] "m"  LAS
 SG_ RLR_ElkOBJ3_Width : 13|11@0+ (0.01,0) [0|12] "m"  LAS
 SG_ RLR_ElkOBJ3_Type : 0|3@0+ (1,0) [0|7] ""  LAS
 SG_ RLR_ElkOBJ3_Track_ID : 7|7@0+ (1,0) [0|127] ""  LAS

BO_ 1882 LAS_75A: 8 LAS

BO_ 1899 LAS_76B: 8 LAS

CM_ BO_ 676 " ";
CM_ SG_ 676 LCDAR_CRCCheck_2AF " ";
CM_ SG_ 676 LCDAR_RollingCounter_2AF "rolling counter ";
CM_ SG_ 676 LCDAR_ELK_oAlert " ";
CM_ SG_ 676 LCDAR_ELK_oStatus " ";
CM_ SG_ 676 LCDAR_Left_ELK_oAlert " ";
CM_ BO_ 1426 " ";
CM_ SG_ 1426 LAS_NotSleep_BYTE7BIT1 " ";
CM_ SG_ 1426 LAS_NotSleep_BYTE7BIT0 " ";
CM_ SG_ 1426 LAS_WakeUp_BYTE4BIT1 " ";
CM_ SG_ 1426 LAS_WakeUp_BYTE4BIT0 " ";
CM_ BO_ 80 " ";
CM_ BO_ 384 " ";
CM_ BO_ 392 " ";
CM_ SG_ 392 TCU_ShiftinProgressValid "AT/DCT ";
CM_ SG_ 392 TCU_ShiftinProgress "AT/DCT ";
CM_ SG_ 392 TCU_CRCCheck_188 " ";
CM_ SG_ 392 TCU_RollingCounter_188 "AT/DCT
rollingcounter ";
CM_ BO_ 580 " ";
CM_ BO_ 632 " ";
CM_ BO_ 664 " ";
CM_ BO_ 832 " ";
CM_ BO_ 870 " ";
CM_ BO_ 903 " ";
CM_ BO_ 1287 " ";
CM_ SG_ 1287 HU_FCWSetting " ";
CM_ BO_ 1302 " ";
CM_ BO_ 1328 " ";
CM_ BO_ 378 " ";
CM_ SG_ 378 ESP_CRCCheck_197 " ";
CM_ BO_ 382 " ";
CM_ BO_ 398 " ";
CM_ BO_ 424 " ";
CM_ SG_ 424 TCU_ActualGear "AT/DCT ";
CM_ SG_ 424 TCU_ActualGearValid "AT/DCT ";
CM_ SG_ 424 TCU_GearShiftPosition "AT/DCT
ACMAT ";
CM_ SG_ 424 TCU_ShiftPostionValid "AT/DCT
ACMAT ";
CM_ SG_ 424 TCU_RollingCounter_1A8 "AT/DCT
ACMAT
rollingcounter ";
CM_ BO_ 523 " ";
CM_ SG_ 523 ESP_RollingCounter_277 "rollingcounter ";
CM_ SG_ 523 ESP_RollingCounter_258 "258 ";
CM_ SG_ 523 ESP_RollingCounter_208 "rollingcounter ";
CM_ SG_ 523 ESP_RollingCounter_206 "rollingcounter ";
CM_ SG_ 523 ESP_MasCylBrakePressureValid "258 ";
CM_ SG_ 523 ESP_MasCylBrakePressure "indicatedthepressureofbrakemastercylinder,butnotthepressureofbrake ";
CM_ SG_ 523 ESP_CRCCheck_277 " ";
CM_ SG_ 523 ESP_CRCCheck_258 "258 ";
CM_ SG_ 523 ESP_CRCCheck_208 " ";
CM_ SG_ 523 ESP_CRCCheck_206 " ";
CM_ BO_ 591 " ";
CM_ BO_ 651 " ";
CM_ BO_ 721 " ";
CM_ BO_ 943 " ";
CM_ BO_ 947 " ";
CM_ BO_ 957 " ";
CM_ SG_ 957 HU_ELKEnable " ";
CM_ SG_ 957 HU_TLAEnable " ";
CM_ BO_ 964 " ";
CM_ SG_ 964 HU_CRCCheck_3C7 " ";
CM_ SG_ 964 HU_RollingCounter_3C7 " ";
CM_ SG_ 964 HU_CRCCheck_3C6 " ";
CM_ SG_ 964 HU_RollingCounter_3C6 " ";
CM_ SG_ 964 HU_CRCCheck_3C4 " ";
CM_ SG_ 964 HU_RollingCounter_3C4 " ";
CM_ SG_ 964 HU_CRCCheck_3C2 " ";
CM_ SG_ 964 HU_RollingCounter_3C2 " ";
CM_ SG_ 964 HU_MapMatchStatus " ";
CM_ SG_ 964 HU_MapDataUpdateStatus " ";
CM_ SG_ 964 HU_SlopeGradient_300m " ";
CM_ SG_ 964 HU_RoadCurvature_600m " ";
CM_ SG_ 964 HU_RoadCurvature_400m " ";
CM_ SG_ 964 HU_RoadCurvature_300m " ";
CM_ SG_ 964 HU_RoadCurvature_100m " ";
CM_ SG_ 964 HU_RoadCurvature_90m " ";
CM_ SG_ 964 HU_RoadCurvature_80m " ";
CM_ SG_ 964 HU_RoadCurvature_70m " ";
CM_ SG_ 964 HU_RoadCurvature_60m " ";
CM_ SG_ 964 HU_RoadCurvature_50m " ";
CM_ SG_ 964 HU_RoadCurvature_40m " ";
CM_ SG_ 964 HU_RoadCurvature_30m " ";
CM_ SG_ 964 HU_RoadCurvature_20m " ";
CM_ SG_ 964 HU_RoadCurvature_10m " ";
CM_ SG_ 964 HU_Road_TrafficFlow " ";
CM_ SG_ 964 HU_Lane_Changtype " ";
CM_ SG_ 964 HU_To_NumchangeOfLanes_Dist " ";
CM_ SG_ 964 HU_To_Branch_Dis " ";
CM_ SG_ 964 HU_BranchInfo " ";
CM_ SG_ 964 HU_To_TrafficAccident_Dis " ";
CM_ SG_ 964 HU_TrafficAccident_Info " ";
CM_ SG_ 964 HU_To_Construction_Dis " ";
CM_ SG_ 964 HU_Construction_Info " ";
CM_ SG_ 964 HU_TollDis " ";
CM_ SG_ 964 HU_TollInfo " ";
CM_ SG_ 964 HU_FallingRockDi " ";
CM_ SG_ 964 HU_FallingRockInfo " ";
CM_ SG_ 964 HU_LaneCnt " ";
CM_ SG_ 964 HU_ForwardRoadType " ";
CM_ SG_ 964 HU_RampSide " ";
CM_ BO_ 1021 " ";
CM_ BO_ 1023 " ";
CM_ BO_ 1684 " ";
CM_ BO_ 652 "MFS_LIN_2 ";
CM_ BO_ 800 " ";
CM_ SG_ 800 GW_ResetReq " ";
CM_ BO_ 922 " ";
CM_ SG_ 922 LAS_CRCCheck_3C0 "
 ";
CM_ SG_ 922 LAS_RollingCounter_3C0 "rolling counter ";
CM_ SG_ 922 LAS_CRCCheck_3D4 "
 ";
CM_ SG_ 922 LAS_RollingCounter_3D4 "rolling counter ";
CM_ SG_ 922 LAS_TLAStopLine_HostLane " ";
CM_ SG_ 922 LAS_TLADistance_HostLane " ";
CM_ SG_ 922 LAS_TLACountDownTime_HostLane " ";
CM_ SG_ 922 LAS_TSRMandatorySign " ";
CM_ SG_ 922 LAS_TSRWarningSign " ";
CM_ SG_ 922 LAS_TSRProhibitionSign " ";
CM_ SG_ 922 LAS_CRCCheck_332 "
 ";
CM_ SG_ 922 LAS_RollingCounter_332 "rolling counter ";
CM_ SG_ 922 LAS_CRCCheck_37D " ";
CM_ SG_ 922 LAS_RollingCounter_37D "rolling counter ";
CM_ SG_ 922 LAS_TLAArrowDirection_RightLane " ";
CM_ SG_ 922 LAS_TLAObjectType_RightLane " ";
CM_ SG_ 922 LAS_TLAObjectStatus_RightLane " ";
CM_ SG_ 922 LAS_TLAObjectColour_RightLane " ";
CM_ SG_ 922 LAS_TLAObjectDetection_RightLane " ";
CM_ SG_ 922 LAS_TLAArrowDirection_LeftLane " ";
CM_ SG_ 922 LAS_TLAObjectType_LeftLane " ";
CM_ SG_ 922 LAS_TLAObjectStatus_LeftLane " ";
CM_ SG_ 922 LAS_TLAObjectColour_LeftLane " ";
CM_ SG_ 922 LAS_TLAObjectDetection_LeftLane " ";
CM_ SG_ 922 LAS_TLAArrowDirection_HostLane " ";
CM_ SG_ 922 LAS_TLAObjectStatus_HostLane " ";
CM_ SG_ 922 LAS_TLAObjectType_HostLane " ";
CM_ SG_ 922 LAS_TLAObjectColour_HostLane " ";
CM_ SG_ 922 LAS_TLAObjectDetection_HostLane " ";
CM_ SG_ 922 LAS_TLAWarninglevel " ";
CM_ SG_ 922 LAS_TLAStatus " ";
CM_ SG_ 922 LAS_TLAEnable " ";
CM_ BO_ 1000 " ";
CM_ BO_ 999 " ";
CM_ BO_ 583 " ";
CM_ BO_ 738 " ";
CM_ BO_ 739 " ";
CM_ BO_ 1882 "DLC 8
CANFD ";
BA_DEF_  "BusType" STRING ;
BA_DEF_ SG_  "GenSigSendType" ENUM  "Cyclic","OnWrite","OnWriteWithRepetition","OnChange","OnChangeWithRepetition","IfActive","IfActiveWithRepetition","NoSigSendType","NotUsed","NotUsed","NotUsed","NotUsed","NotUsed";
BA_DEF_ SG_  "GenSigCycleTime" INT 0 0;
BA_DEF_ SG_  "GenSigInvalidValue" STRING ;
BA_DEF_ SG_  "GenSigStartValue" INT 0 0;
BA_DEF_ BO_  "VFrameFormat" ENUM  "StandardCAN","ExtendedCAN","reserved","reserved","reserved","reserved","reserved","reserved","reserved","reserved","reserved","reserved","reserved","reserved","StandardCAN_FD","ExtendedCAN_FD";
BA_DEF_ BO_  "CANFD_BRS" ENUM  "0","1";
BA_DEF_ BO_  "GenMsgCycleTime" INT 0 65535;
BA_DEF_ BO_  "GenMsgILSupport" ENUM  "No","Yes";
BA_DEF_ BO_  "GenMsgSendType" ENUM  "Cyclic","Event","NotUsed","NotUsed","NotUsed","Cyclic","NotUsed","IfActive","NoMsgSendType","NotUsed";
BA_DEF_ BO_  "NmMessage" ENUM  "No","Yes";
BA_DEF_ BU_  "ILUsed" ENUM  "No","Yes";
BA_DEF_ BU_  "NmStationAddress" HEX 0 0;
BA_DEF_ BU_  "NodeLayerModules" STRING ;
BA_DEF_DEF_  "BusType" "";
BA_DEF_DEF_  "GenSigSendType" "Cyclic";
BA_DEF_DEF_  "GenSigCycleTime" 0;
BA_DEF_DEF_  "GenSigInvalidValue" "/";
BA_DEF_DEF_  "GenSigStartValue" 0;
BA_DEF_DEF_  "VFrameFormat" "StandardCAN";
BA_DEF_DEF_  "CANFD_BRS" "1";
BA_DEF_DEF_  "GenMsgCycleTime" 0;
BA_DEF_DEF_  "GenMsgILSupport" "Yes";
BA_DEF_DEF_  "GenMsgSendType" "NoMsgSendType";
BA_DEF_DEF_  "NmMessage" "No";
BA_DEF_DEF_  "ILUsed" "Yes";
BA_DEF_DEF_  "NmStationAddress" 0;
BA_DEF_DEF_  "NodeLayerModules" "OSEKNM01.dll,CANoeILNLVector.dll";
BA_ "BusType" "CAN";
BA_ "NmMessage" BO_ 1107 1;
BA_ "GenMsgCycleTime" BO_ 1107 1000;
BA_ "NmMessage" BO_ 1030 1;
BA_ "GenMsgCycleTime" BO_ 1030 1000;
BA_ "NmMessage" BO_ 1106 1;
BA_ "GenMsgCycleTime" BO_ 1106 1000;
BA_ "GenMsgSendType" BO_ 676 0;
BA_ "GenMsgCycleTime" BO_ 676 50;
BA_ "VFrameFormat" BO_ 676 14;
BA_ "GenMsgSendType" BO_ 1426 0;
BA_ "GenMsgCycleTime" BO_ 1426 1000;
BA_ "VFrameFormat" BO_ 1426 14;
BA_ "GenMsgSendType" BO_ 80 0;
BA_ "GenMsgCycleTime" BO_ 80 500;
BA_ "VFrameFormat" BO_ 80 14;
BA_ "GenMsgSendType" BO_ 384 0;
BA_ "GenMsgCycleTime" BO_ 384 10;
BA_ "VFrameFormat" BO_ 384 14;
BA_ "GenMsgSendType" BO_ 392 0;
BA_ "GenMsgCycleTime" BO_ 392 10;
BA_ "VFrameFormat" BO_ 392 14;
BA_ "GenMsgSendType" BO_ 580 0;
BA_ "GenMsgCycleTime" BO_ 580 20;
BA_ "VFrameFormat" BO_ 580 14;
BA_ "GenMsgSendType" BO_ 632 0;
BA_ "GenMsgCycleTime" BO_ 632 20;
BA_ "VFrameFormat" BO_ 632 14;
BA_ "GenMsgSendType" BO_ 664 0;
BA_ "GenMsgCycleTime" BO_ 664 40;
BA_ "VFrameFormat" BO_ 664 14;
BA_ "GenMsgSendType" BO_ 832 0;
BA_ "GenMsgCycleTime" BO_ 832 100;
BA_ "VFrameFormat" BO_ 832 14;
BA_ "GenMsgSendType" BO_ 870 0;
BA_ "GenMsgCycleTime" BO_ 870 100;
BA_ "VFrameFormat" BO_ 870 14;
BA_ "GenMsgSendType" BO_ 903 0;
BA_ "GenMsgCycleTime" BO_ 903 100;
BA_ "VFrameFormat" BO_ 903 14;
BA_ "GenMsgSendType" BO_ 1287 1;
BA_ "VFrameFormat" BO_ 1287 14;
BA_ "GenMsgSendType" BO_ 1302 0;
BA_ "GenMsgCycleTime" BO_ 1302 1000;
BA_ "VFrameFormat" BO_ 1302 14;
BA_ "GenMsgSendType" BO_ 1328 0;
BA_ "GenMsgCycleTime" BO_ 1328 500;
BA_ "VFrameFormat" BO_ 1328 14;
BA_ "GenMsgSendType" BO_ 378 0;
BA_ "GenMsgCycleTime" BO_ 378 10;
BA_ "VFrameFormat" BO_ 378 14;
BA_ "GenMsgSendType" BO_ 382 0;
BA_ "GenMsgCycleTime" BO_ 382 10;
BA_ "VFrameFormat" BO_ 382 14;
BA_ "GenMsgSendType" BO_ 398 0;
BA_ "GenMsgCycleTime" BO_ 398 10;
BA_ "VFrameFormat" BO_ 398 14;
BA_ "GenMsgSendType" BO_ 424 0;
BA_ "GenMsgCycleTime" BO_ 424 10;
BA_ "VFrameFormat" BO_ 424 14;
BA_ "GenMsgSendType" BO_ 523 0;
BA_ "GenMsgCycleTime" BO_ 523 20;
BA_ "VFrameFormat" BO_ 523 14;
BA_ "GenMsgSendType" BO_ 591 0;
BA_ "GenMsgCycleTime" BO_ 591 20;
BA_ "VFrameFormat" BO_ 591 14;
BA_ "GenMsgSendType" BO_ 651 0;
BA_ "GenMsgCycleTime" BO_ 651 40;
BA_ "VFrameFormat" BO_ 651 14;
BA_ "GenMsgSendType" BO_ 721 0;
BA_ "GenMsgCycleTime" BO_ 721 40;
BA_ "VFrameFormat" BO_ 721 14;
BA_ "GenMsgSendType" BO_ 943 0;
BA_ "GenMsgCycleTime" BO_ 943 100;
BA_ "VFrameFormat" BO_ 943 14;
BA_ "GenMsgSendType" BO_ 947 0;
BA_ "GenMsgCycleTime" BO_ 947 100;
BA_ "VFrameFormat" BO_ 947 14;
BA_ "GenMsgSendType" BO_ 957 0;
BA_ "GenMsgCycleTime" BO_ 957 100;
BA_ "VFrameFormat" BO_ 957 14;
BA_ "GenMsgSendType" BO_ 964 0;
BA_ "GenMsgCycleTime" BO_ 964 100;
BA_ "VFrameFormat" BO_ 964 14;
BA_ "GenMsgSendType" BO_ 1021 0;
BA_ "GenMsgCycleTime" BO_ 1021 100;
BA_ "VFrameFormat" BO_ 1021 14;
BA_ "GenMsgSendType" BO_ 1023 0;
BA_ "GenMsgCycleTime" BO_ 1023 100;
BA_ "VFrameFormat" BO_ 1023 14;
BA_ "GenMsgSendType" BO_ 1684 0;
BA_ "GenMsgCycleTime" BO_ 1684 500;
BA_ "VFrameFormat" BO_ 1684 14;
BA_ "GenMsgSendType" BO_ 652 0;
BA_ "GenMsgCycleTime" BO_ 652 40;
BA_ "VFrameFormat" BO_ 652 14;
BA_ "GenMsgSendType" BO_ 800 0;
BA_ "GenMsgCycleTime" BO_ 800 100;
BA_ "VFrameFormat" BO_ 800 14;
BA_ "GenMsgSendType" BO_ 922 0;
BA_ "GenMsgCycleTime" BO_ 922 100;
BA_ "VFrameFormat" BO_ 922 14;
BA_ "GenMsgSendType" BO_ 1000 0;
BA_ "GenMsgCycleTime" BO_ 1000 100;
BA_ "VFrameFormat" BO_ 1000 14;
BA_ "GenMsgSendType" BO_ 999 0;
BA_ "GenMsgCycleTime" BO_ 999 100;
BA_ "VFrameFormat" BO_ 999 14;
BA_ "GenMsgSendType" BO_ 583 0;
BA_ "GenMsgCycleTime" BO_ 583 20;
BA_ "VFrameFormat" BO_ 583 14;
BA_ "GenMsgSendType" BO_ 738 0;
BA_ "GenMsgCycleTime" BO_ 738 50;
BA_ "VFrameFormat" BO_ 738 14;
BA_ "GenMsgSendType" BO_ 739 0;
BA_ "GenMsgCycleTime" BO_ 739 50;
BA_ "VFrameFormat" BO_ 739 14;
BA_ "GenMsgSendType" BO_ 1882 1;
BA_ "VFrameFormat" BO_ 1882 14;
BA_ "GenMsgSendType" BO_ 1899 1;
BA_ "VFrameFormat" BO_ 1899 14;
BA_ "GenSigStartValue" SG_ 1030 GW_NMSourceAddress 6;
BA_ "GenSigCycleTime" SG_ 676 LCDAR_CRCCheck_2AF 50;
BA_ "GenSigCycleTime" SG_ 676 LCDAR_RollingCounter_2AF 50;
BA_ "GenSigCycleTime" SG_ 676 LCDAR_ELK_oAlert 50;
BA_ "GenSigInvalidValue" SG_ 676 LCDAR_ELK_oStatus "3";
BA_ "GenSigCycleTime" SG_ 676 LCDAR_ELK_oStatus 50;
BA_ "GenSigCycleTime" SG_ 676 LCDAR_Left_ELK_oAlert 50;
BA_ "GenSigCycleTime" SG_ 1426 LAS_NotSleep_BYTE7BIT1 1000;
BA_ "GenSigCycleTime" SG_ 1426 LAS_NotSleep_BYTE7BIT0 1000;
BA_ "GenSigCycleTime" SG_ 1426 LAS_WakeUp_BYTE4BIT1 1000;
BA_ "GenSigCycleTime" SG_ 1426 LAS_WakeUp_BYTE4BIT0 1000;
BA_ "GenSigCycleTime" SG_ 80 SRS_WarningLampStatus 500;
BA_ "GenSigCycleTime" SG_ 80 SRS_DriverBuckleSwitchStatus 500;
BA_ "GenSigCycleTime" SG_ 80 SRS_RollingCounter_id050 500;
BA_ "GenSigCycleTime" SG_ 80 SRS_CrashOutputStatusCheckSum 500;
BA_ "GenSigCycleTime" SG_ 80 SRS_CrashOutputStatus 500;
BA_ "GenSigCycleTime" SG_ 80 SRS_CRCCheck_50 500;
BA_ "GenSigCycleTime" SG_ 384 SAS_CRCCheck 10;
BA_ "GenSigCycleTime" SG_ 384 SAS_RollingCounter 10;
BA_ "GenSigInvalidValue" SG_ 384 SAS_SteeringAngleSpeed "255";
BA_ "GenSigCycleTime" SG_ 384 SAS_SteeringAngleSpeed 10;
BA_ "GenSigInvalidValue" SG_ 384 SAS_SteeringAngle "32767";
BA_ "GenSigCycleTime" SG_ 384 SAS_SteeringAngle 10;
BA_ "GenSigInvalidValue" SG_ 384 SAS_SASFailure "1";
BA_ "GenSigCycleTime" SG_ 384 SAS_SASFailure 10;
BA_ "GenSigCycleTime" SG_ 384 SAS_Calibrated 10;
BA_ "GenSigInvalidValue" SG_ 384 SAS_SteeringAngleValid "1";
BA_ "GenSigCycleTime" SG_ 384 SAS_SteeringAngleValid 10;
BA_ "GenSigInvalidValue" SG_ 392 TCU_ShiftinProgressValid "1";
BA_ "GenSigCycleTime" SG_ 392 TCU_ShiftinProgressValid 10;
BA_ "GenSigCycleTime" SG_ 392 TCU_ShiftinProgress 10;
BA_ "GenSigCycleTime" SG_ 392 TCU_CRCCheck_188 10;
BA_ "GenSigCycleTime" SG_ 392 TCU_RollingCounter_188 10;
BA_ "GenSigCycleTime" SG_ 580 ACC_AEBActive 20;
BA_ "GenSigCycleTime" SG_ 632 ESP_IMUCalibrated 10;
BA_ "GenSigCycleTime" SG_ 632 ESP_YawRateValid_R 10;
BA_ "GenSigCycleTime" SG_ 632 ESP_LatAccelValid 10;
BA_ "GenSigCycleTime" SG_ 632 ESP_LongAccelValid 10;
BA_ "GenSigCycleTime" SG_ 632 ESP_YawRateValid 10;
BA_ "GenSigInvalidValue" SG_ 632 ESP_YawRate "16383";
BA_ "GenSigCycleTime" SG_ 632 ESP_YawRate 10;
BA_ "GenSigCycleTime" SG_ 632 ESP_RollingCounter_278 10;
BA_ "GenSigInvalidValue" SG_ 632 ESP_LongAccel "1023";
BA_ "GenSigCycleTime" SG_ 632 ESP_LongAccel 10;
BA_ "GenSigInvalidValue" SG_ 632 ESP_LatAccel "255";
BA_ "GenSigCycleTime" SG_ 632 ESP_LatAccel 10;
BA_ "GenSigCycleTime" SG_ 632 ESP_CRCCheck_278 10;
BA_ "GenSigCycleTime" SG_ 664 BCM_LeftRearDoorStatus 40;
BA_ "GenSigInvalidValue" SG_ 832 AC_FrBlowType "7";
BA_ "GenSigCycleTime" SG_ 832 AC_FrBlowType 100;
BA_ "GenSigStartValue" SG_ 870 AC_EnvironmentalTemp 255;
BA_ "GenSigInvalidValue" SG_ 870 AC_EnvironmentalTemp "255";
BA_ "GenSigCycleTime" SG_ 870 AC_EnvironmentalTemp 100;
BA_ "GenSigInvalidValue" SG_ 870 AC_EnvironmentalTempVD "1";
BA_ "GenSigCycleTime" SG_ 870 AC_EnvironmentalTempVD 100;
BA_ "GenSigStartValue" SG_ 903 BCM_RainfallLevel 14;
BA_ "GenSigInvalidValue" SG_ 903 BCM_RainfallLevel "15";
BA_ "GenSigCycleTime" SG_ 903 BCM_RainfallLevel 100;
BA_ "GenSigInvalidValue" SG_ 903 BCM_FrontWiperStatus "3";
BA_ "GenSigCycleTime" SG_ 903 BCM_FrontWiperStatus 100;
BA_ "GenSigCycleTime" SG_ 1302 HU_LocalTimeSystem 1000;
BA_ "GenSigInvalidValue" SG_ 1302 HU_LocalTimeSecond "0";
BA_ "GenSigCycleTime" SG_ 1302 HU_LocalTimeSecond 1000;
BA_ "GenSigInvalidValue" SG_ 1302 HU_LocalTimeMinute "0";
BA_ "GenSigCycleTime" SG_ 1302 HU_LocalTimeMinute 1000;
BA_ "GenSigInvalidValue" SG_ 1302 HU_LocalTimeHour "0";
BA_ "GenSigCycleTime" SG_ 1302 HU_LocalTimeHour 1000;
BA_ "GenSigStartValue" SG_ 1302 HU_LocalTimeDate 1;
BA_ "GenSigInvalidValue" SG_ 1302 HU_LocalTimeDate "1";
BA_ "GenSigCycleTime" SG_ 1302 HU_LocalTimeDate 1000;
BA_ "GenSigInvalidValue" SG_ 1302 HU_LocalTimeYear "0";
BA_ "GenSigCycleTime" SG_ 1302 HU_LocalTimeYear 1000;
BA_ "GenSigStartValue" SG_ 1302 HU_LocalTimeMonth 1;
BA_ "GenSigInvalidValue" SG_ 1302 HU_LocalTimeMonth "1";
BA_ "GenSigCycleTime" SG_ 1302 HU_LocalTimeMonth 1000;
BA_ "GenSigInvalidValue" SG_ 1302 HU_LocalTimeValid "1";
BA_ "GenSigCycleTime" SG_ 1302 HU_LocalTimeValid 1000;
BA_ "GenSigInvalidValue" SG_ 1302 HU_CurrentLocationLatitude "268435455";
BA_ "GenSigCycleTime" SG_ 1302 HU_CurrentLocationLatitude 1000;
BA_ "GenSigInvalidValue" SG_ 1302 HU_CurrentLocationLongitude "536870911";
BA_ "GenSigCycleTime" SG_ 1302 HU_CurrentLocationLongitude 1000;
BA_ "GenSigInvalidValue" SG_ 1302 HU_CurrentLocationValid "1";
BA_ "GenSigCycleTime" SG_ 1302 HU_CurrentLocationValid 1000;
BA_ "GenSigInvalidValue" SG_ 1328 IP_TotalOdometer "16777215";
BA_ "GenSigCycleTime" SG_ 1328 IP_TotalOdometer 500;
BA_ "GenSigInvalidValue" SG_ 378 ESP_VehicleSpeed "8191";
BA_ "GenSigCycleTime" SG_ 378 ESP_VehicleSpeed 10;
BA_ "GenSigInvalidValue" SG_ 378 ESP_VehicleSpeedValid "1";
BA_ "GenSigCycleTime" SG_ 378 ESP_VehicleSpeedValid 10;
BA_ "GenSigCycleTime" SG_ 378 ESP_TCSFailStatus 10;
BA_ "GenSigCycleTime" SG_ 378 ESP_RollingCounter_187 10;
BA_ "GenSigStartValue" SG_ 378 ESP_ESPFunctionStatus 1;
BA_ "GenSigCycleTime" SG_ 378 ESP_ESPFunctionStatus 10;
BA_ "GenSigCycleTime" SG_ 378 ESP_ESPActiveStatus 10;
BA_ "GenSigCycleTime" SG_ 378 ESP_CRCCheck_197 10;
BA_ "GenSigCycleTime" SG_ 378 ESP_CRCCheck_187 10;
BA_ "GenSigCycleTime" SG_ 378 ESP_ABSFailStatus 10;
BA_ "GenSigCycleTime" SG_ 378 ESP_ABSActiveStatus 10;
BA_ "GenSigInvalidValue" SG_ 382 EPS_ADS_Abortfeedback "15";
BA_ "GenSigCycleTime" SG_ 382 EPS_ADS_Abortfeedback 10;
BA_ "GenSigInvalidValue" SG_ 382 EPS_LatCtrlActive "0";
BA_ "GenSigCycleTime" SG_ 382 EPS_LatCtrlActive 10;
BA_ "GenSigInvalidValue" SG_ 382 EPS_LatCtrlAvailabilityStatus "2";
BA_ "GenSigCycleTime" SG_ 382 EPS_LatCtrlAvailabilityStatus 10;
BA_ "GenSigCycleTime" SG_ 382 EPS_CRCCheck_17E 10;
BA_ "GenSigCycleTime" SG_ 382 EPS_RollingCounter_17E 10;
BA_ "GenSigInvalidValue" SG_ 382 EPS_MeasuredTorsionBarTorqValid "1";
BA_ "GenSigCycleTime" SG_ 382 EPS_MeasuredTorsionBarTorqValid 10;
BA_ "GenSigStartValue" SG_ 382 EPS_MeasuredTorsionBarTorque 2048;
BA_ "GenSigInvalidValue" SG_ 382 EPS_MeasuredTorsionBarTorque "4095";
BA_ "GenSigCycleTime" SG_ 382 EPS_MeasuredTorsionBarTorque 10;
BA_ "GenSigCycleTime" SG_ 398 EMS_CRCCheck_1A6 10;
BA_ "GenSigCycleTime" SG_ 398 EMS_RollingCounter_1A6 10;
BA_ "GenSigCycleTime" SG_ 398 EMS_EngineStatus 10;
BA_ "GenSigInvalidValue" SG_ 398 EMS_AccPedal "255";
BA_ "GenSigCycleTime" SG_ 398 EMS_AccPedal 10;
BA_ "GenSigInvalidValue" SG_ 398 EMS_EngineSpeed "65535";
BA_ "GenSigCycleTime" SG_ 398 EMS_EngineSpeed 10;
BA_ "GenSigInvalidValue" SG_ 398 EMS_BrakePedalStatus "3";
BA_ "GenSigCycleTime" SG_ 398 EMS_BrakePedalStatus 10;
BA_ "GenSigInvalidValue" SG_ 398 EMS_RealAccPedal "255";
BA_ "GenSigCycleTime" SG_ 398 EMS_RealAccPedal 10;
BA_ "GenSigCycleTime" SG_ 424 TCU_FastOnMode 10;
BA_ "GenSigInvalidValue" SG_ 424 TCU_ActualGear "15";
BA_ "GenSigCycleTime" SG_ 424 TCU_ActualGear 10;
BA_ "GenSigInvalidValue" SG_ 424 TCU_ActualGearValid "1";
BA_ "GenSigCycleTime" SG_ 424 TCU_ActualGearValid 10;
BA_ "GenSigStartValue" SG_ 424 TCU_GearShiftPosition 14;
BA_ "GenSigInvalidValue" SG_ 424 TCU_GearShiftPosition "15";
BA_ "GenSigCycleTime" SG_ 424 TCU_GearShiftPosition 10;
BA_ "GenSigInvalidValue" SG_ 424 TCU_ShiftPostionValid "1";
BA_ "GenSigCycleTime" SG_ 424 TCU_ShiftPostionValid 10;
BA_ "GenSigCycleTime" SG_ 424 TCU_CRCCheck_1A8 10;
BA_ "GenSigCycleTime" SG_ 424 TCU_RollingCounter_1A8 10;
BA_ "GenSigInvalidValue" SG_ 523 Wheel_Speed_FL_Pulse "255";
BA_ "GenSigCycleTime" SG_ 523 Wheel_Speed_FL_Pulse 20;
BA_ "GenSigInvalidValue" SG_ 523 Wheel_Speed_FR_Pulse "255";
BA_ "GenSigCycleTime" SG_ 523 Wheel_Speed_FR_Pulse 20;
BA_ "GenSigInvalidValue" SG_ 523 ESP_Vehicle_Speed_Reference "8191";
BA_ "GenSigCycleTime" SG_ 523 ESP_Vehicle_Speed_Reference 20;
BA_ "GenSigInvalidValue" SG_ 523 Wheel_Speed_RR_Valid_Data "1";
BA_ "GenSigCycleTime" SG_ 523 Wheel_Speed_RR_Valid_Data 20;
BA_ "GenSigInvalidValue" SG_ 523 Wheel_Speed_RR_Pulse "255";
BA_ "GenSigCycleTime" SG_ 523 Wheel_Speed_RR_Pulse 20;
BA_ "GenSigCycleTime" SG_ 523 Wheel_Speed_RR_Direction 20;
BA_ "GenSigInvalidValue" SG_ 523 Wheel_Speed_RR_Data "8191";
BA_ "GenSigCycleTime" SG_ 523 Wheel_Speed_RR_Data 20;
BA_ "GenSigInvalidValue" SG_ 523 Wheel_Speed_RL_Valid_Data "1";
BA_ "GenSigCycleTime" SG_ 523 Wheel_Speed_RL_Valid_Data 20;
BA_ "GenSigInvalidValue" SG_ 523 Wheel_Speed_RL_Pulse "255";
BA_ "GenSigCycleTime" SG_ 523 Wheel_Speed_RL_Pulse 20;
BA_ "GenSigInvalidValue" SG_ 523 Wheel_Speed_RL_Direction "3";
BA_ "GenSigCycleTime" SG_ 523 Wheel_Speed_RL_Direction 20;
BA_ "GenSigInvalidValue" SG_ 523 Wheel_Speed_RL_Data "8191";
BA_ "GenSigCycleTime" SG_ 523 Wheel_Speed_RL_Data 20;
BA_ "GenSigInvalidValue" SG_ 523 Wheel_Speed_FR_Valid_Data "1";
BA_ "GenSigCycleTime" SG_ 523 Wheel_Speed_FR_Valid_Data 20;
BA_ "GenSigInvalidValue" SG_ 523 Wheel_Speed_FR_Direction "3";
BA_ "GenSigCycleTime" SG_ 523 Wheel_Speed_FR_Direction 20;
BA_ "GenSigInvalidValue" SG_ 523 Wheel_Speed_FR_Data "8191";
BA_ "GenSigCycleTime" SG_ 523 Wheel_Speed_FR_Data 20;
BA_ "GenSigInvalidValue" SG_ 523 Wheel_Speed_FL_Valid_Data "1";
BA_ "GenSigCycleTime" SG_ 523 Wheel_Speed_FL_Valid_Data 20;
BA_ "GenSigInvalidValue" SG_ 523 Wheel_Speed_FL_Direction "3";
BA_ "GenSigCycleTime" SG_ 523 Wheel_Speed_FL_Direction 20;
BA_ "GenSigInvalidValue" SG_ 523 Wheel_Speed_FL_Data "8191";
BA_ "GenSigCycleTime" SG_ 523 Wheel_Speed_FL_Data 20;
BA_ "GenSigCycleTime" SG_ 523 ESP_VehicleStandstill 20;
BA_ "GenSigCycleTime" SG_ 523 ESP_VDCActive 20;
BA_ "GenSigCycleTime" SG_ 523 ESP_TCSActive 20;
BA_ "GenSigCycleTime" SG_ 523 ESP_RollingCounter_277 20;
BA_ "GenSigCycleTime" SG_ 523 ESP_RollingCounter_258 20;
BA_ "GenSigCycleTime" SG_ 523 ESP_RollingCounter_208 20;
BA_ "GenSigCycleTime" SG_ 523 ESP_RollingCounter_206 20;
BA_ "GenSigCycleTime" SG_ 523 ESP_PrefillAvailable 20;
BA_ "GenSigCycleTime" SG_ 523 ESP_PrefillActive 20;
BA_ "GenSigCycleTime" SG_ 523 ESP_OnlyABSActive 20;
BA_ "GenSigCycleTime" SG_ 523 ESP_MasCylBrakePressureValid 20;
BA_ "GenSigInvalidValue" SG_ 523 ESP_MasCylBrakePressure "4095";
BA_ "GenSigCycleTime" SG_ 523 ESP_MasCylBrakePressure 20;
BA_ "GenSigCycleTime" SG_ 523 ESP_CRCCheck_277 20;
BA_ "GenSigCycleTime" SG_ 523 ESP_CRCCheck_258 20;
BA_ "GenSigCycleTime" SG_ 523 ESP_CRCCheck_208 20;
BA_ "GenSigCycleTime" SG_ 523 ESP_CRCCheck_206 20;
BA_ "GenSigCycleTime" SG_ 523 ESP_BrakeForce 20;
BA_ "GenSigCycleTime" SG_ 523 ESP_AWBavailable 20;
BA_ "GenSigCycleTime" SG_ 523 ESP_AWBactive 20;
BA_ "GenSigCycleTime" SG_ 523 ESP_AEBdecActive 20;
BA_ "GenSigCycleTime" SG_ 523 ESP_AEBAvailable 20;
BA_ "GenSigCycleTime" SG_ 523 ESP_ABAavailable 20;
BA_ "GenSigCycleTime" SG_ 523 ESP_ABAactive 20;
BA_ "GenSigInvalidValue" SG_ 591 EPS_ConcussAvailabilityStatus "2";
BA_ "GenSigCycleTime" SG_ 591 EPS_ConcussAvailabilityStatus 20;
BA_ "GenSigStartValue" SG_ 591 EPS_TorqueAssistMode 3;
BA_ "GenSigCycleTime" SG_ 591 EPS_TorqueAssistMode 20;
BA_ "GenSigCycleTime" SG_ 591 EPS_IACC_abortreason 20;
BA_ "GenSigCycleTime" SG_ 591 EPS_CRCCheck_24F 20;
BA_ "GenSigCycleTime" SG_ 591 EPS_RollingCounter_24F 20;
BA_ "GenSigInvalidValue" SG_ 651 LCM_LASSwitch "3";
BA_ "GenSigCycleTime" SG_ 651 LCM_LASSwitch 40;
BA_ "GenSigInvalidValue" SG_ 651 BCM_TurnIndicatorLeft "3";
BA_ "GenSigCycleTime" SG_ 651 BCM_TurnIndicatorLeft 40;
BA_ "GenSigInvalidValue" SG_ 651 BCM_TurnIndicatorRight "3";
BA_ "GenSigCycleTime" SG_ 651 BCM_TurnIndicatorRight 40;
BA_ "GenSigInvalidValue" SG_ 651 BCM_emergencylightstatus "3";
BA_ "GenSigCycleTime" SG_ 651 BCM_emergencylightstatus 40;
BA_ "GenSigCycleTime" SG_ 651 BCM_DriverDoorStatus 40;
BA_ "GenSigInvalidValue" SG_ 651 BCM_LowBeamStatus "3";
BA_ "GenSigCycleTime" SG_ 651 BCM_LowBeamStatus 40;
BA_ "GenSigInvalidValue" SG_ 651 BCM_HighBeamStatus "3";
BA_ "GenSigCycleTime" SG_ 651 BCM_HighBeamStatus 40;
BA_ "GenSigInvalidValue" SG_ 651 BCM_TurnLightSwitchSts "3";
BA_ "GenSigCycleTime" SG_ 651 BCM_TurnLightSwitchSts 40;
BA_ "GenSigCycleTime" SG_ 721 BCM_TrunkDoorStatus 40;
BA_ "GenSigCycleTime" SG_ 721 BCM_RightRearDoorStatus 40;
BA_ "GenSigCycleTime" SG_ 721 BCM_PassengerDoorStatus 40;
BA_ "GenSigCycleTime" SG_ 943 HU_CRCCheck_3AF 100;
BA_ "GenSigCycleTime" SG_ 943 HU_RollingCounter_3AF 100;
BA_ "GenSigStartValue" SG_ 943 HU_RampDistance 1023;
BA_ "GenSigInvalidValue" SG_ 943 HU_RampDistance "1023";
BA_ "GenSigCycleTime" SG_ 943 HU_RampDistance 100;
BA_ "GenSigInvalidValue" SG_ 943 HU_NavSpeedLimitType "0";
BA_ "GenSigCycleTime" SG_ 943 HU_NavSpeedLimitType 100;
BA_ "GenSigStartValue" SG_ 943 HU_CurveDistance 63;
BA_ "GenSigInvalidValue" SG_ 943 HU_CurveDistance "63";
BA_ "GenSigCycleTime" SG_ 943 HU_CurveDistance 100;
BA_ "GenSigInvalidValue" SG_ 943 HU_EnterCurveInfo "0";
BA_ "GenSigCycleTime" SG_ 943 HU_EnterCurveInfo 100;
BA_ "GenSigInvalidValue" SG_ 943 HU_NavCurrentRoadType "0";
BA_ "GenSigCycleTime" SG_ 943 HU_NavCurrentRoadType 100;
BA_ "GenSigInvalidValue" SG_ 943 HU_EnterRampInfo "0";
BA_ "GenSigCycleTime" SG_ 943 HU_EnterRampInfo 100;
BA_ "GenSigInvalidValue" SG_ 943 HU_RampInfo "0";
BA_ "GenSigCycleTime" SG_ 943 HU_RampInfo 100;
BA_ "GenSigInvalidValue" SG_ 943 HU_NavCountryCode "0";
BA_ "GenSigCycleTime" SG_ 943 HU_NavCountryCode 100;
BA_ "GenSigInvalidValue" SG_ 943 HU_NavStatus "1";
BA_ "GenSigCycleTime" SG_ 943 HU_NavStatus 100;
BA_ "GenSigInvalidValue" SG_ 943 HU_NavSpeedLimitUnits "0";
BA_ "GenSigCycleTime" SG_ 943 HU_NavSpeedLimitUnits 100;
BA_ "GenSigInvalidValue" SG_ 943 HU_NavSpeedLimitStatus "1";
BA_ "GenSigCycleTime" SG_ 943 HU_NavSpeedLimitStatus 100;
BA_ "GenSigStartValue" SG_ 943 HU_NavSpeedLimit 254;
BA_ "GenSigInvalidValue" SG_ 943 HU_NavSpeedLimit "255";
BA_ "GenSigCycleTime" SG_ 943 HU_NavSpeedLimit 100;
BA_ "GenSigInvalidValue" SG_ 947 BCM_RearFoglampStatus "3";
BA_ "GenSigCycleTime" SG_ 947 BCM_RearFoglampStatus 100;
BA_ "GenSigInvalidValue" SG_ 957 HU_ELKEnable "0";
BA_ "GenSigCycleTime" SG_ 957 HU_ELKEnable 100;
BA_ "GenSigInvalidValue" SG_ 957 HU_TLAEnable "0";
BA_ "GenSigCycleTime" SG_ 957 HU_TLAEnable 100;
BA_ "GenSigCycleTime" SG_ 964 HU_CRCCheck_3C7 100;
BA_ "GenSigCycleTime" SG_ 964 HU_RollingCounter_3C7 100;
BA_ "GenSigCycleTime" SG_ 964 HU_CRCCheck_3C6 100;
BA_ "GenSigCycleTime" SG_ 964 HU_RollingCounter_3C6 100;
BA_ "GenSigCycleTime" SG_ 964 HU_CRCCheck_3C4 100;
BA_ "GenSigCycleTime" SG_ 964 HU_RollingCounter_3C4 100;
BA_ "GenSigCycleTime" SG_ 964 HU_CRCCheck_3C2 100;
BA_ "GenSigCycleTime" SG_ 964 HU_RollingCounter_3C2 100;
BA_ "GenSigInvalidValue" SG_ 964 HU_MapMatchStatus "3";
BA_ "GenSigCycleTime" SG_ 964 HU_MapMatchStatus 100;
BA_ "GenSigInvalidValue" SG_ 964 HU_MapDataUpdateStatus "7";
BA_ "GenSigCycleTime" SG_ 964 HU_MapDataUpdateStatus 100;
BA_ "GenSigStartValue" SG_ 964 HU_SlopeGradient_300m 1023;
BA_ "GenSigInvalidValue" SG_ 964 HU_SlopeGradient_300m "1023";
BA_ "GenSigCycleTime" SG_ 964 HU_SlopeGradient_300m 100;
BA_ "GenSigStartValue" SG_ 964 HU_RoadCurvature_600m 511;
BA_ "GenSigInvalidValue" SG_ 964 HU_RoadCurvature_600m "1023";
BA_ "GenSigCycleTime" SG_ 964 HU_RoadCurvature_600m 100;
BA_ "GenSigStartValue" SG_ 964 HU_RoadCurvature_400m 511;
BA_ "GenSigInvalidValue" SG_ 964 HU_RoadCurvature_400m "1023";
BA_ "GenSigCycleTime" SG_ 964 HU_RoadCurvature_400m 100;
BA_ "GenSigStartValue" SG_ 964 HU_RoadCurvature_300m 511;
BA_ "GenSigInvalidValue" SG_ 964 HU_RoadCurvature_300m "1023";
BA_ "GenSigCycleTime" SG_ 964 HU_RoadCurvature_300m 100;
BA_ "GenSigStartValue" SG_ 964 HU_RoadCurvature_100m 511;
BA_ "GenSigInvalidValue" SG_ 964 HU_RoadCurvature_100m "1023";
BA_ "GenSigCycleTime" SG_ 964 HU_RoadCurvature_100m 100;
BA_ "GenSigStartValue" SG_ 964 HU_RoadCurvature_90m 511;
BA_ "GenSigInvalidValue" SG_ 964 HU_RoadCurvature_90m "1023";
BA_ "GenSigCycleTime" SG_ 964 HU_RoadCurvature_90m 100;
BA_ "GenSigStartValue" SG_ 964 HU_RoadCurvature_80m 511;
BA_ "GenSigInvalidValue" SG_ 964 HU_RoadCurvature_80m "1023";
BA_ "GenSigCycleTime" SG_ 964 HU_RoadCurvature_80m 100;
BA_ "GenSigStartValue" SG_ 964 HU_RoadCurvature_70m 511;
BA_ "GenSigInvalidValue" SG_ 964 HU_RoadCurvature_70m "1023";
BA_ "GenSigCycleTime" SG_ 964 HU_RoadCurvature_70m 100;
BA_ "GenSigStartValue" SG_ 964 HU_RoadCurvature_60m 511;
BA_ "GenSigInvalidValue" SG_ 964 HU_RoadCurvature_60m "1023";
BA_ "GenSigCycleTime" SG_ 964 HU_RoadCurvature_60m 100;
BA_ "GenSigStartValue" SG_ 964 HU_RoadCurvature_50m 511;
BA_ "GenSigInvalidValue" SG_ 964 HU_RoadCurvature_50m "1023";
BA_ "GenSigCycleTime" SG_ 964 HU_RoadCurvature_50m 100;
BA_ "GenSigStartValue" SG_ 964 HU_RoadCurvature_40m 511;
BA_ "GenSigInvalidValue" SG_ 964 HU_RoadCurvature_40m "1023";
BA_ "GenSigCycleTime" SG_ 964 HU_RoadCurvature_40m 100;
BA_ "GenSigStartValue" SG_ 964 HU_RoadCurvature_30m 511;
BA_ "GenSigInvalidValue" SG_ 964 HU_RoadCurvature_30m "1023";
BA_ "GenSigCycleTime" SG_ 964 HU_RoadCurvature_30m 100;
BA_ "GenSigStartValue" SG_ 964 HU_RoadCurvature_20m 511;
BA_ "GenSigInvalidValue" SG_ 964 HU_RoadCurvature_20m "1023";
BA_ "GenSigCycleTime" SG_ 964 HU_RoadCurvature_20m 100;
BA_ "GenSigStartValue" SG_ 964 HU_RoadCurvature_10m 511;
BA_ "GenSigInvalidValue" SG_ 964 HU_RoadCurvature_10m "1023";
BA_ "GenSigCycleTime" SG_ 964 HU_RoadCurvature_10m 100;
BA_ "GenSigInvalidValue" SG_ 964 HU_Road_TrafficFlow "7";
BA_ "GenSigCycleTime" SG_ 964 HU_Road_TrafficFlow 100;
BA_ "GenSigStartValue" SG_ 964 HU_Lane_Changtype 3;
BA_ "GenSigInvalidValue" SG_ 964 HU_Lane_Changtype "3";
BA_ "GenSigCycleTime" SG_ 964 HU_Lane_Changtype 100;
BA_ "GenSigStartValue" SG_ 964 HU_To_NumchangeOfLanes_Dist 63;
BA_ "GenSigInvalidValue" SG_ 964 HU_To_NumchangeOfLanes_Dist "63";
BA_ "GenSigCycleTime" SG_ 964 HU_To_NumchangeOfLanes_Dist 100;
BA_ "GenSigStartValue" SG_ 964 HU_To_Branch_Dis 63;
BA_ "GenSigInvalidValue" SG_ 964 HU_To_Branch_Dis "63";
BA_ "GenSigCycleTime" SG_ 964 HU_To_Branch_Dis 100;
BA_ "GenSigInvalidValue" SG_ 964 HU_BranchInfo "0";
BA_ "GenSigCycleTime" SG_ 964 HU_BranchInfo 100;
BA_ "GenSigStartValue" SG_ 964 HU_To_TrafficAccident_Dis 63;
BA_ "GenSigInvalidValue" SG_ 964 HU_To_TrafficAccident_Dis "63";
BA_ "GenSigCycleTime" SG_ 964 HU_To_TrafficAccident_Dis 100;
BA_ "GenSigStartValue" SG_ 964 HU_TrafficAccident_Info 3;
BA_ "GenSigInvalidValue" SG_ 964 HU_TrafficAccident_Info "3";
BA_ "GenSigCycleTime" SG_ 964 HU_TrafficAccident_Info 100;
BA_ "GenSigStartValue" SG_ 964 HU_To_Construction_Dis 63;
BA_ "GenSigInvalidValue" SG_ 964 HU_To_Construction_Dis "63";
BA_ "GenSigCycleTime" SG_ 964 HU_To_Construction_Dis 100;
BA_ "GenSigStartValue" SG_ 964 HU_Construction_Info 3;
BA_ "GenSigInvalidValue" SG_ 964 HU_Construction_Info "3";
BA_ "GenSigCycleTime" SG_ 964 HU_Construction_Info 100;
BA_ "GenSigStartValue" SG_ 964 HU_TollDis 63;
BA_ "GenSigInvalidValue" SG_ 964 HU_TollDis "63";
BA_ "GenSigCycleTime" SG_ 964 HU_TollDis 100;
BA_ "GenSigStartValue" SG_ 964 HU_TollInfo 3;
BA_ "GenSigInvalidValue" SG_ 964 HU_TollInfo "3";
BA_ "GenSigCycleTime" SG_ 964 HU_TollInfo 100;
BA_ "GenSigStartValue" SG_ 964 HU_FallingRockDi 63;
BA_ "GenSigInvalidValue" SG_ 964 HU_FallingRockDi "63";
BA_ "GenSigCycleTime" SG_ 964 HU_FallingRockDi 100;
BA_ "GenSigStartValue" SG_ 964 HU_FallingRockInfo 3;
BA_ "GenSigInvalidValue" SG_ 964 HU_FallingRockInfo "3";
BA_ "GenSigCycleTime" SG_ 964 HU_FallingRockInfo 100;
BA_ "GenSigInvalidValue" SG_ 964 HU_LaneCnt "0";
BA_ "GenSigCycleTime" SG_ 964 HU_LaneCnt 100;
BA_ "GenSigInvalidValue" SG_ 964 HU_ForwardRoadType "0";
BA_ "GenSigCycleTime" SG_ 964 HU_ForwardRoadType 100;
BA_ "GenSigInvalidValue" SG_ 964 HU_RampSide "0";
BA_ "GenSigCycleTime" SG_ 964 HU_RampSide 100;
BA_ "GenSigCycleTime" SG_ 964 HU_CRCCheck_3B8 100;
BA_ "GenSigCycleTime" SG_ 964 HU_RollingCounter_3B8 100;
BA_ "GenSigInvalidValue" SG_ 964 HU_NavGuiganceStatus "3";
BA_ "GenSigCycleTime" SG_ 964 HU_NavGuiganceStatus 100;
BA_ "GenSigStartValue" SG_ 964 HU_SlopeDistance 63;
BA_ "GenSigInvalidValue" SG_ 964 HU_SlopeDistance "63";
BA_ "GenSigCycleTime" SG_ 964 HU_SlopeDistance 100;
BA_ "GenSigInvalidValue" SG_ 964 HU_Byroad "3";
BA_ "GenSigCycleTime" SG_ 964 HU_Byroad 100;
BA_ "GenSigStartValue" SG_ 964 HU_TunnelLength 63;
BA_ "GenSigInvalidValue" SG_ 964 HU_TunnelLength "63";
BA_ "GenSigCycleTime" SG_ 964 HU_TunnelLength 100;
BA_ "GenSigStartValue" SG_ 964 HU_RoadCurvatureFar 511;
BA_ "GenSigInvalidValue" SG_ 964 HU_RoadCurvatureFar "1023";
BA_ "GenSigCycleTime" SG_ 964 HU_RoadCurvatureFar 100;
BA_ "GenSigStartValue" SG_ 964 HU_TunnelDistance 63;
BA_ "GenSigInvalidValue" SG_ 964 HU_TunnelDistance "63";
BA_ "GenSigCycleTime" SG_ 964 HU_TunnelDistance 100;
BA_ "GenSigStartValue" SG_ 964 HU_RoadCurvature 511;
BA_ "GenSigInvalidValue" SG_ 964 HU_RoadCurvature "1023";
BA_ "GenSigCycleTime" SG_ 964 HU_RoadCurvature 100;
BA_ "GenSigInvalidValue" SG_ 964 HU_EnterSlopeInfo "0";
BA_ "GenSigCycleTime" SG_ 964 HU_EnterSlopeInfo 100;
BA_ "GenSigInvalidValue" SG_ 964 HU_EnterTunnelInfo "0";
BA_ "GenSigCycleTime" SG_ 964 HU_EnterTunnelInfo 100;
BA_ "GenSigInvalidValue" SG_ 1021 BCM_PowerManageLevel "7";
BA_ "GenSigCycleTime" SG_ 1021 BCM_PowerManageLevel 100;
BA_ "GenSigCycleTime" SG_ 1023 BCM_RightLowBeamError 100;
BA_ "GenSigCycleTime" SG_ 1023 BCM_LeftLowBeamError 100;
BA_ "GenSigInvalidValue" SG_ 1023 BCM_AutoHeadlightSts "0";
BA_ "GenSigCycleTime" SG_ 1023 BCM_AutoHeadlightSts 100;
BA_ "GenSigInvalidValue" SG_ 1023 BCM_FrontFoglampStatus "3";
BA_ "GenSigCycleTime" SG_ 1023 BCM_FrontFoglampStatus 100;
BA_ "GenSigCycleTime" SG_ 1684 LAS_DTC2_Status 500;
BA_ "GenSigCycleTime" SG_ 1684 LAS_DTC2_LowByte 500;
BA_ "GenSigCycleTime" SG_ 1684 LAS_DTC2_MiddByte 500;
BA_ "GenSigCycleTime" SG_ 1684 LAS_DTC2_HighByte 500;
BA_ "GenSigCycleTime" SG_ 1684 LAS_DTC1_Status 500;
BA_ "GenSigCycleTime" SG_ 1684 LAS_DTC1_LowByte 500;
BA_ "GenSigCycleTime" SG_ 1684 LAS_DTC1_MiddByte 500;
BA_ "GenSigCycleTime" SG_ 1684 LAS_DTC1_HighByte 500;
BA_ "GenSigCycleTime" SG_ 652 GW_MFS_CRCCheck_28C 40;
BA_ "GenSigCycleTime" SG_ 652 GW_MFS_RollingCounter_28C 40;
BA_ "GenSigInvalidValue" SG_ 652 GW_MFS_IACCenable_switch_signal "3";
BA_ "GenSigCycleTime" SG_ 652 GW_MFS_IACCenable_switch_signal 40;
BA_ "GenSigInvalidValue" SG_ 800 GW_ResetReq "295";
BA_ "GenSigCycleTime" SG_ 800 GW_ResetReq 100;
BA_ "GenSigInvalidValue" SG_ 922 LAS_ResetSts "7";
BA_ "GenSigCycleTime" SG_ 922 LAS_ResetSts 100;
BA_ "GenSigCycleTime" SG_ 922 ACC_RollingCounter_39A 100;
BA_ "GenSigCycleTime" SG_ 922 ACC_CRCCheck_39A 100;
BA_ "GenSigInvalidValue" SG_ 922 LAS_TSRRightLaneStatus "7";
BA_ "GenSigCycleTime" SG_ 922 LAS_TSRRightLaneStatus 100;
BA_ "GenSigInvalidValue" SG_ 922 LAS_TSRLeftLaneStatus "7";
BA_ "GenSigCycleTime" SG_ 922 LAS_TSRLeftLaneStatus 100;
BA_ "GenSigCycleTime" SG_ 922 LAS_CRCCheck_3C0 100;
BA_ "GenSigCycleTime" SG_ 922 LAS_RollingCounter_3C0 100;
BA_ "GenSigInvalidValue" SG_ 922 LAS_TSRRightLaneSpdLimit "254";
BA_ "GenSigCycleTime" SG_ 922 LAS_TSRRightLaneSpdLimit 100;
BA_ "GenSigInvalidValue" SG_ 922 LAS_TSRLeftLaneSpdLimit "254";
BA_ "GenSigCycleTime" SG_ 922 LAS_TSRLeftLaneSpdLimit 100;
BA_ "GenSigCycleTime" SG_ 922 LAS_CRCCheck_3D4 100;
BA_ "GenSigCycleTime" SG_ 922 LAS_RollingCounter_3D4 100;
BA_ "GenSigStartValue" SG_ 922 LAS_TLAStopLine_HostLane 255;
BA_ "GenSigCycleTime" SG_ 922 LAS_TLAStopLine_HostLane 100;
BA_ "GenSigStartValue" SG_ 922 LAS_TLADistance_HostLane 255;
BA_ "GenSigCycleTime" SG_ 922 LAS_TLADistance_HostLane 100;
BA_ "GenSigCycleTime" SG_ 922 LAS_TLACountDownTime_HostLane 100;
BA_ "GenSigCycleTime" SG_ 922 LAS_TSRMandatorySign 100;
BA_ "GenSigCycleTime" SG_ 922 LAS_TSRWarningSign 100;
BA_ "GenSigCycleTime" SG_ 922 LAS_TSRProhibitionSign 100;
BA_ "GenSigCycleTime" SG_ 922 LAS_CRCCheck_332 100;
BA_ "GenSigCycleTime" SG_ 922 LAS_RollingCounter_332 100;
BA_ "GenSigCycleTime" SG_ 922 LAS_OverspeedSoundWarningEnSt 100;
BA_ "GenSigCycleTime" SG_ 922 LAS_TSREnable 100;
BA_ "GenSigCycleTime" SG_ 922 LAS_HMAEnableStatus 100;
BA_ "GenSigCycleTime" SG_ 922 LAS_HMALightDistribution 100;
BA_ "GenSigInvalidValue" SG_ 922 LAS_HMAStatus "3";
BA_ "GenSigCycleTime" SG_ 922 LAS_HMAStatus 100;
BA_ "GenSigInvalidValue" SG_ 922 LAS_TSRHostSpdLimitUnits "0";
BA_ "GenSigCycleTime" SG_ 922 LAS_TSRHostSpdLimitUnits 100;
BA_ "GenSigInvalidValue" SG_ 922 LAS_TSRHostSpdLimit "254";
BA_ "GenSigCycleTime" SG_ 922 LAS_TSRHostSpdLimit 100;
BA_ "GenSigInvalidValue" SG_ 922 LAS_TSRStatus "7";
BA_ "GenSigCycleTime" SG_ 922 LAS_TSRStatus 100;
BA_ "GenSigInvalidValue" SG_ 922 LAS_FrontCameraCalibrationStatus "3";
BA_ "GenSigCycleTime" SG_ 922 LAS_FrontCameraCalibrationStatus 100;
BA_ "GenSigInvalidValue" SG_ 922 LAS_FrontCameraFailureStatus "3";
BA_ "GenSigCycleTime" SG_ 922 LAS_FrontCameraFailureStatus 100;
BA_ "GenSigStartValue" SG_ 922 LAS_OverspeedWarningOffset 10;
BA_ "GenSigCycleTime" SG_ 922 LAS_OverspeedWarningOffset 100;
BA_ "GenSigCycleTime" SG_ 922 LAS_OverspeedWarningEnableStatus 100;
BA_ "GenSigCycleTime" SG_ 922 LAS_OverspeedSoundWarning 100;
BA_ "GenSigCycleTime" SG_ 922 LAS_OverspeedVisualWarning 100;
BA_ "GenSigCycleTime" SG_ 922 LAS_CRCCheck_37D 100;
BA_ "GenSigCycleTime" SG_ 922 LAS_RollingCounter_37D 100;
BA_ "GenSigCycleTime" SG_ 922 LAS_TLAArrowDirection_RightLane 100;
BA_ "GenSigCycleTime" SG_ 922 LAS_TLAObjectType_RightLane 100;
BA_ "GenSigCycleTime" SG_ 922 LAS_TLAObjectStatus_RightLane 100;
BA_ "GenSigCycleTime" SG_ 922 LAS_TLAObjectColour_RightLane 100;
BA_ "GenSigCycleTime" SG_ 922 LAS_TLAObjectDetection_RightLane 100;
BA_ "GenSigCycleTime" SG_ 922 LAS_TLAArrowDirection_LeftLane 100;
BA_ "GenSigCycleTime" SG_ 922 LAS_TLAObjectType_LeftLane 100;
BA_ "GenSigCycleTime" SG_ 922 LAS_TLAObjectStatus_LeftLane 100;
BA_ "GenSigCycleTime" SG_ 922 LAS_TLAObjectColour_LeftLane 100;
BA_ "GenSigCycleTime" SG_ 922 LAS_TLAObjectDetection_LeftLane 100;
BA_ "GenSigCycleTime" SG_ 922 LAS_TLAArrowDirection_HostLane 100;
BA_ "GenSigCycleTime" SG_ 922 LAS_TLAObjectStatus_HostLane 100;
BA_ "GenSigCycleTime" SG_ 922 LAS_TLAObjectType_HostLane 100;
BA_ "GenSigCycleTime" SG_ 922 LAS_TLAObjectColour_HostLane 100;
BA_ "GenSigCycleTime" SG_ 922 LAS_TLAObjectDetection_HostLane 100;
BA_ "GenSigCycleTime" SG_ 922 LAS_TLAWarninglevel 100;
BA_ "GenSigInvalidValue" SG_ 922 LAS_TLAStatus "3";
BA_ "GenSigCycleTime" SG_ 922 LAS_TLAStatus 100;
BA_ "GenSigCycleTime" SG_ 922 LAS_TLAEnable 100;
BA_ "GenSigStartValue" SG_ 1000 BCM_SOF_Q_STATE 3;
BA_ "GenSigInvalidValue" SG_ 1000 BCM_SOF_Q_STATE "3";
BA_ "GenSigCycleTime" SG_ 1000 BCM_SOF_Q_STATE 100;
BA_ "GenSigStartValue" SG_ 1000 BCM_SOF_Q 255;
BA_ "GenSigInvalidValue" SG_ 1000 BCM_SOF_Q "255";
BA_ "GenSigCycleTime" SG_ 1000 BCM_SOF_Q 100;
BA_ "GenSigInvalidValue" SG_ 999 BCM_Status_Temp "0";
BA_ "GenSigCycleTime" SG_ 999 BCM_Status_Temp 100;
BA_ "GenSigStartValue" SG_ 999 BCM_T_BATT 255;
BA_ "GenSigInvalidValue" SG_ 999 BCM_T_BATT "255";
BA_ "GenSigCycleTime" SG_ 999 BCM_T_BATT 100;
BA_ "GenSigCycleTime" SG_ 583 APA_APAOnOff 20;
BA_ "GenSigCycleTime" SG_ 738 RLR_CRCCheck_2E2 50;
BA_ "GenSigCycleTime" SG_ 738 RLR_RollingCounter_2E2 50;
BA_ "GenSigInvalidValue" SG_ 738 RLR_ElkOBJ2_Measured "0";
BA_ "GenSigCycleTime" SG_ 738 RLR_ElkOBJ2_Measured 50;
BA_ "GenSigInvalidValue" SG_ 738 RLR_ElkOBJ2_ExistProb "0";
BA_ "GenSigCycleTime" SG_ 738 RLR_ElkOBJ2_ExistProb 50;
BA_ "GenSigInvalidValue" SG_ 738 RLR_ElkOBJ2_Location "0";
BA_ "GenSigCycleTime" SG_ 738 RLR_ElkOBJ2_Location 50;
BA_ "GenSigCycleTime" SG_ 738 RLR_ElkOBJ2_RelAx 50;
BA_ "GenSigCycleTime" SG_ 738 RLR_ElkOBJ2_RelAy 50;
BA_ "GenSigCycleTime" SG_ 738 RLR_ElkOBJ2_RelVx 50;
BA_ "GenSigCycleTime" SG_ 738 RLR_ElkOBJ2_RelVy 50;
BA_ "GenSigCycleTime" SG_ 738 RLR_ElkOBJ2_Dx 50;
BA_ "GenSigCycleTime" SG_ 738 RLR_ElkOBJ2_RefPointLoc 50;
BA_ "GenSigCycleTime" SG_ 738 RLR_ElkOBJ2_Dy 50;
BA_ "GenSigCycleTime" SG_ 738 RLR_ElkOBJ2_HeadingAngle 50;
BA_ "GenSigCycleTime" SG_ 738 RLR_ElkOBJ2_Length 50;
BA_ "GenSigCycleTime" SG_ 738 RLR_ElkOBJ2_Height 50;
BA_ "GenSigCycleTime" SG_ 738 RLR_ElkOBJ2_Width 50;
BA_ "GenSigInvalidValue" SG_ 738 RLR_ElkOBJ2_Type "0";
BA_ "GenSigCycleTime" SG_ 738 RLR_ElkOBJ2_Type 50;
BA_ "GenSigCycleTime" SG_ 738 RLR_ElkOBJ2_Track_ID 50;
BA_ "GenSigCycleTime" SG_ 738 RLR_ElkOBJ2_RefPointDx 50;
BA_ "GenSigCycleTime" SG_ 738 RLR_ElkOBJ2_RefPointDy 50;
BA_ "GenSigCycleTime" SG_ 738 RLR_ElkOBJ2_ObstacleProb 50;
BA_ "GenSigCycleTime" SG_ 738 RLR_ElkOBJ1_RefPointDx 50;
BA_ "GenSigCycleTime" SG_ 738 RLR_ElkOBJ1_RefPointDy 50;
BA_ "GenSigCycleTime" SG_ 738 RLR_ElkOBJ1_ObstacleProb 50;
BA_ "GenSigInvalidValue" SG_ 738 RLR_ElkOBJ1_Measured "0";
BA_ "GenSigCycleTime" SG_ 738 RLR_ElkOBJ1_Measured 50;
BA_ "GenSigInvalidValue" SG_ 738 RLR_ElkOBJ1_ExistProb "0";
BA_ "GenSigCycleTime" SG_ 738 RLR_ElkOBJ1_ExistProb 50;
BA_ "GenSigInvalidValue" SG_ 738 RLR_ElkOBJ1_Location "0";
BA_ "GenSigCycleTime" SG_ 738 RLR_ElkOBJ1_Location 50;
BA_ "GenSigCycleTime" SG_ 738 RLR_ElkOBJ1_RelAx 50;
BA_ "GenSigCycleTime" SG_ 738 RLR_ElkOBJ1_RelAy 50;
BA_ "GenSigCycleTime" SG_ 738 RLR_ElkOBJ1_RelVx 50;
BA_ "GenSigCycleTime" SG_ 738 RLR_ElkOBJ1_RelVy 50;
BA_ "GenSigCycleTime" SG_ 738 RLR_ElkOBJ1_Dx 50;
BA_ "GenSigCycleTime" SG_ 738 RLR_ElkOBJ1_RefPointLoc 50;
BA_ "GenSigCycleTime" SG_ 738 RLR_ElkOBJ1_Dy 50;
BA_ "GenSigCycleTime" SG_ 738 RLR_ElkOBJ1_HeadingAngle 50;
BA_ "GenSigCycleTime" SG_ 738 RLR_ElkOBJ1_Length 50;
BA_ "GenSigCycleTime" SG_ 738 RLR_ElkOBJ1_Height 50;
BA_ "GenSigCycleTime" SG_ 738 RLR_ElkOBJ1_Width 50;
BA_ "GenSigInvalidValue" SG_ 738 RLR_ElkOBJ1_Type "0";
BA_ "GenSigCycleTime" SG_ 738 RLR_ElkOBJ1_Type 50;
BA_ "GenSigCycleTime" SG_ 738 RLR_ElkOBJ1_Track_ID 50;
BA_ "GenSigCycleTime" SG_ 739 RLR_CRCCheck_2E3 50;
BA_ "GenSigCycleTime" SG_ 739 RLR_RollingCounter_2E3 50;
BA_ "GenSigInvalidValue" SG_ 739 RLR_ElkOBJ4_Measured "0";
BA_ "GenSigCycleTime" SG_ 739 RLR_ElkOBJ4_Measured 50;
BA_ "GenSigInvalidValue" SG_ 739 RLR_ElkOBJ4_ExistProb "0";
BA_ "GenSigCycleTime" SG_ 739 RLR_ElkOBJ4_ExistProb 50;
BA_ "GenSigInvalidValue" SG_ 739 RLR_ElkOBJ4_Location "0";
BA_ "GenSigCycleTime" SG_ 739 RLR_ElkOBJ4_Location 50;
BA_ "GenSigCycleTime" SG_ 739 RLR_ElkOBJ4_RelAx 50;
BA_ "GenSigCycleTime" SG_ 739 RLR_ElkOBJ4_RelAy 50;
BA_ "GenSigCycleTime" SG_ 739 RLR_ElkOBJ4_RelVx 50;
BA_ "GenSigCycleTime" SG_ 739 RLR_ElkOBJ4_RelVy 50;
BA_ "GenSigCycleTime" SG_ 739 RLR_ElkOBJ4_Dx 50;
BA_ "GenSigCycleTime" SG_ 739 RLR_ElkOBJ4_RefPointLoc 50;
BA_ "GenSigCycleTime" SG_ 739 RLR_ElkOBJ4_Dy 50;
BA_ "GenSigCycleTime" SG_ 739 RLR_ElkOBJ4_HeadingAngle 50;
BA_ "GenSigCycleTime" SG_ 739 RLR_ElkOBJ4_Length 50;
BA_ "GenSigCycleTime" SG_ 739 RLR_ElkOBJ4_Height 50;
BA_ "GenSigCycleTime" SG_ 739 RLR_ElkOBJ4_Width 50;
BA_ "GenSigInvalidValue" SG_ 739 RLR_ElkOBJ4_Type "0";
BA_ "GenSigCycleTime" SG_ 739 RLR_ElkOBJ4_Type 50;
BA_ "GenSigCycleTime" SG_ 739 RLR_ElkOBJ4_Track_ID 50;
BA_ "GenSigCycleTime" SG_ 739 RLR_ElkOBJ4_RefPointDx 50;
BA_ "GenSigCycleTime" SG_ 739 RLR_ElkOBJ4_RefPointDy 50;
BA_ "GenSigCycleTime" SG_ 739 RLR_ElkOBJ4_ObstacleProb 50;
BA_ "GenSigCycleTime" SG_ 739 RLR_ElkOBJ3_RefPointDx 50;
BA_ "GenSigCycleTime" SG_ 739 RLR_ElkOBJ3_RefPointDy 50;
BA_ "GenSigCycleTime" SG_ 739 RLR_ElkOBJ3_ObstacleProb 50;
BA_ "GenSigInvalidValue" SG_ 739 RLR_ElkOBJ3_Measured "0";
BA_ "GenSigCycleTime" SG_ 739 RLR_ElkOBJ3_Measured 50;
BA_ "GenSigInvalidValue" SG_ 739 RLR_ElkOBJ3_ExistProb "0";
BA_ "GenSigCycleTime" SG_ 739 RLR_ElkOBJ3_ExistProb 50;
BA_ "GenSigInvalidValue" SG_ 739 RLR_ElkOBJ3_Location "0";
BA_ "GenSigCycleTime" SG_ 739 RLR_ElkOBJ3_Location 50;
BA_ "GenSigCycleTime" SG_ 739 RLR_ElkOBJ3_RelAx 50;
BA_ "GenSigCycleTime" SG_ 739 RLR_ElkOBJ3_RelAy 50;
BA_ "GenSigCycleTime" SG_ 739 RLR_ElkOBJ3_RelVx 50;
BA_ "GenSigCycleTime" SG_ 739 RLR_ElkOBJ3_RelVy 50;
BA_ "GenSigCycleTime" SG_ 739 RLR_ElkOBJ3_Dx 50;
BA_ "GenSigCycleTime" SG_ 739 RLR_ElkOBJ3_RefPointLoc 50;
BA_ "GenSigCycleTime" SG_ 739 RLR_ElkOBJ3_Dy 50;
BA_ "GenSigCycleTime" SG_ 739 RLR_ElkOBJ3_HeadingAngle 50;
BA_ "GenSigCycleTime" SG_ 739 RLR_ElkOBJ3_Length 50;
BA_ "GenSigCycleTime" SG_ 739 RLR_ElkOBJ3_Height 50;
BA_ "GenSigCycleTime" SG_ 739 RLR_ElkOBJ3_Width 50;
BA_ "GenSigInvalidValue" SG_ 739 RLR_ElkOBJ3_Type "0";
BA_ "GenSigCycleTime" SG_ 739 RLR_ElkOBJ3_Type 50;
BA_ "GenSigCycleTime" SG_ 739 RLR_ElkOBJ3_Track_ID 50;
VAL_ 676 LCDAR_ELK_oAlert 0 "No warning" 1 "level 1" 2 "level 2" 3 "Reserved" ;
VAL_ 676 LCDAR_ELK_oStatus 0 "OFF()" 1 "Inactive()" 2 "Active" 3 "Failure" ;
VAL_ 676 LCDAR_Left_ELK_oAlert 0 "No warning" 1 "level 1" 2 "level 2" 3 "Reserved" ;
VAL_ 1426 LAS_NotSleep_BYTE7BIT1 0 "Inactive" 1 " IGNON/OFF" ;
VAL_ 1426 LAS_NotSleep_BYTE7BIT0 0 "Inactive" 1 " CAN" ;
VAL_ 1426 LAS_WakeUp_BYTE4BIT1 0 "Inactive" 1 " IGIG" ;
VAL_ 1426 LAS_WakeUp_BYTE4BIT0 0 "Inactive" 1 " CAN" ;
VAL_ 80 SRS_WarningLampStatus 0 "Lamp off" 1 "Lamp on" 2 "Lamp Flashing" 3 "Not Used" ;
VAL_ 80 SRS_DriverBuckleSwitchStatus 0 "Buckled" 1 "Unbuckle " 2 "Not Used" 3 "Not Used Default value: 0x0" ;
VAL_ 80 SRS_CrashOutputStatusCheckSum 0 "(SRS_CrashOutputStatus) XOR 0xF" ;
VAL_ 80 SRS_CrashOutputStatus 0 "No Crash" 1 "crash " 2 "Not Used" ;
VAL_ 80 SRS_CRCCheck_50 0 "0xFFXOR value=0xFFinput data reflected=NoResult data reflected=Nocheck=0x48Magic check=0xC4" ;
VAL_ 384 SAS_SASFailure 0 "No Failure" 1 "Failure" ;
VAL_ 384 SAS_Calibrated 0 "Calibrated" 1 " Not Calibrated" ;
VAL_ 384 SAS_SteeringAngleValid 0 "Valid " 1 "Invalid" ;
VAL_ 392 TCU_ShiftinProgressValid 0 "Valid" 1 "Invalid" ;
VAL_ 392 TCU_ShiftinProgress 0 "Noshift" 1 "Shift" ;
VAL_ 580 ACC_AEBActive 0 " not Active" 1 " Active." ;
VAL_ 632 ESP_IMUCalibrated 0 "Calibrated" 1 "Not Calibrated" ;
VAL_ 632 ESP_YawRateValid_R 0 "Initializing" 1 "Valid" 2 "Invalid" 3 "Reserved" ;
VAL_ 632 ESP_LatAccelValid 0 "Initializing" 1 "Valid" 2 "Invalid" 3 "Reserved" ;
VAL_ 632 ESP_LongAccelValid 0 "Initializing" 1 "Valid" 2 "Invalid" 3 "Reserved" ;
VAL_ 632 ESP_YawRateValid 0 "Valid" 1 "Invalid" ;
VAL_ 664 BCM_LeftRearDoorStatus 0 "Close" 1 "Open" ;
VAL_ 832 AC_FrBlowType 0 "blow face" 1 "blow face/blow feet" 2 "blow feet" 3 "blow fee/defroster" 4 "defroster" 5 "Reserved" 7 "Invalid." ;
VAL_ 870 AC_EnvironmentalTemp 0 "-40~87" 255 "Invalid" ;
VAL_ 870 AC_EnvironmentalTempVD 0 "Valid" 1 "Invalid" ;
VAL_ 903 BCM_RainfallLevel 0 "No rain" 1 "Level 1" 2 "Level 2" 3 "Level 3" 4 "Level 4" 5 "Level 5?" 6 "Level 6" 7 "Level 7" 8 "Level 8" 9 "Level 9" 10 "Level 10" 11 "Level 11" 12 "Level 12" 13 "level 13" 14 "init value" 15 "Invalid value" ;
VAL_ 903 BCM_FrontWiperStatus 0 "OFF" 1 "Low" 2 "High" 3 "Error" ;
VAL_ 1287 HU_FCWSetting 0 "Early" 1 "Normal" 2 "Late" 3 "Off" 4 "Reserved" 7 "Invalid" ;
VAL_ 1287 HU_IACCEnable 0 "Inactive" 1 "Off" 2 "On" 3 "Reserved" ;
VAL_ 1287 HU_LDWShakeLev 0 "inactive" 1 "low" 2 "normal" 3 "high" ;
VAL_ 1287 HU_HMAEnable 0 "off" 1 "on" ;
VAL_ 1287 HU_TSRSwitch 0 "off" 1 "on" ;
VAL_ 1287 HU_LASWarningModeSelection 0 "inactive" 1 "visual" 2 "sound" 3 "vibration" 4 "sound and vibration" 5 "Reserved" ;
VAL_ 1287 HU_LASModeSelection 0 "Inactive" 1 "LDW" 2 "LKA" 3 "LCS" 4 "Reserved" 7 "OFF" ;
VAL_ 1287 HU_OverspeedWarningOffset 0 "" 21 "Reserved" 31 "Invalid." ;
VAL_ 1287 HU_OverspeedWarningEnable 0 "Inactive" 1 "OFF" 2 "ON" 3 "Reserved" ;
VAL_ 1287 HU_OverspeedSoundWarEnable 0 "Inactive" 1 "Off" 2 "On" 3 " Reserved" ;
VAL_ 1302 HU_LocalTimeSystem 0 "24h" 1 "12h" 2 "Reserved" 3 "Invalid" ;
VAL_ 1302 HU_LocalTimeValid 0 "Valid" 1 "Not Valid" ;
VAL_ 1302 HU_CurrentLocationLatitude 134217727 "" ;
VAL_ 1302 HU_CurrentLocationLongitude 268435455 "" ;
VAL_ 1302 HU_CurrentLocationValid 0 "Valid" 1 "Not Valid" ;
VAL_ 378 ESP_VehicleSpeed 0 "0~360km/h" 6401 "Reserved" 8191 "Invalid APA2.0" ;
VAL_ 378 ESP_VehicleSpeedValid 0 "Valid" 1 "NotValid" ;
VAL_ 378 ESP_TCSFailStatus 0 "Noerror" 1 "Error" ;
VAL_ 378 ESP_ESPFunctionStatus 0 "OFF" 1 "ON" ;
VAL_ 378 ESP_ESPActiveStatus 0 "NotActive" 1 "Active" ;
VAL_ 378 ESP_ABSFailStatus 0 "Noerror" 1 "Error" ;
VAL_ 378 ESP_ABSActiveStatus 0 "NotActive" 1 "Active" ;
VAL_ 382 EPS_ADS_Abortfeedback 0 "No Fault" 1 "Adas Speed Invalid" 2 "Adas Signal Invalid " 3 "State Mismatch" 4 "APA Interrupt" 5 "BUS Off" 6 "Both Channels CAN down" 7 "Adas Chassis CAN Down " 8 "ADAS Internal Error" 9 "Speed out of range" 10 "AgAmpErr" 11 "AgGrdtFlt" 12 "Driver Interrupt" 13 "ADAS Req Mode Invld" ;
VAL_ 382 EPS_LatCtrlActive 0 "Not Actived" 1 "Actived" ;
VAL_ 382 EPS_LatCtrlAvailabilityStatus 0 "not Availability " 1 "Availability" 2 "failure" 3 "reserved" ;
VAL_ 382 EPS_MeasuredTorsionBarTorqValid 0 "" 1 "" ;
VAL_ 382 EPS_MeasuredTorsionBarTorque 2048 "" ;
VAL_ 398 EMS_EngineStatus 0 "Stop" 1 "Crank" 2 "Running" 3 "Reserved" ;
VAL_ 398 EMS_EngineSpeed 0 "0~16383.5Rmp" 65535 "Invalid" ;
VAL_ 398 EMS_BrakePedalStatus 0 "NotPressed" 1 "Pressed" 2 "Reserved" 3 "Error" ;
VAL_ 424 TCU_FastOnMode 0 "Off" 1 "On" ;
VAL_ 424 TCU_ActualGear 0 "Neutral" 1 "1stgear" 2 "2ndgear" 3 "3rdgear" 4 "4tgear" 5 "5tgear" 6 "6tgear" 7 "7tgear" 8 "8tgear" 9 "Reverse" 10 "Parking" 11 "Reserved" 12 "Reserved" 13 "Reserved" 14 "Reserved" 15 "Invalid" ;
VAL_ 424 TCU_ActualGearValid 0 "Valid" 1 "Invalid" ;
VAL_ 424 TCU_GearShiftPosition 0 "Parking" 1 "Reverse" 2 "Neutral" 3 "D" 4 "D3" 5 "D2" 6 "L" 7 "M_or_S" 8 "Reserved" 9 "Reserved" 10 "Reserved" 11 "Reserved" 12 "Reserved" 13 "Reserved" 14 "Unreliable" 15 "Invalid" ;
VAL_ 424 TCU_ShiftPostionValid 0 "Valid" 1 "Invalid" ;
VAL_ 523 ESP_Vehicle_Speed_Reference 0 "0~360km/h" 6401 "Reserved" 8191 "Invalid" ;
VAL_ 523 Wheel_Speed_RR_Valid_Data 0 "Valid" 1 "NotValid" ;
VAL_ 523 Wheel_Speed_RR_Direction 0 "Forward" 1 "backward" 2 "Standstill" 3 "Invalid" ;
VAL_ 523 Wheel_Speed_RL_Valid_Data 0 "Valid" 1 "NotValid" ;
VAL_ 523 Wheel_Speed_RL_Direction 0 "Forward" 1 "backward" 2 "Standstill" 3 "Invalid" ;
VAL_ 523 Wheel_Speed_FR_Valid_Data 0 "Valid" 1 "NotValid" ;
VAL_ 523 Wheel_Speed_FR_Direction 0 "Forward" 1 "backward" 2 "Standstill" 3 "Invalid" ;
VAL_ 523 Wheel_Speed_FL_Valid_Data 0 "Valid" 1 "NotValid" ;
VAL_ 523 Wheel_Speed_FL_Direction 0 "Forward" 1 "backward" 2 "Standstill" 3 "Invalid" ;
VAL_ 523 ESP_VehicleStandstill 0 "notstandstill" 1 "standstill" ;
VAL_ 523 ESP_VDCActive 0 "NotActive" 1 "Active" ;
VAL_ 523 ESP_TCSActive 0 "NotActive" 1 "Active" ;
VAL_ 523 ESP_PrefillAvailable 0 "notavailable" 1 "available" ;
VAL_ 523 ESP_PrefillActive 0 "notactive" 1 "active" ;
VAL_ 523 ESP_OnlyABSActive 0 "NotActive" 1 "Active" ;
VAL_ 523 ESP_MasCylBrakePressureValid 0 "Valid" 1 "Invalid" ;
VAL_ 523 ESP_BrakeForce 0 "nobrakeforce" 1 "havebrakeforce" ;
VAL_ 523 ESP_AWBavailable 0 "notavailable" 1 "available" ;
VAL_ 523 ESP_AWBactive 0 "notactive" 1 "active" ;
VAL_ 523 ESP_AEBdecActive 0 "notactive" 1 "active" ;
VAL_ 523 ESP_AEBAvailable 0 "notavailable" 1 "available" ;
VAL_ 523 ESP_ABAavailable 0 "notavailable" 1 "available" ;
VAL_ 523 ESP_ABAactive 0 "notactive" 1 "active" ;
VAL_ 591 EPS_ConcussAvailabilityStatus 0 "Concuss Availability " 1 "Concuss Active" 2 "EPS Concuss failure  EPS" 3 "reserved" ;
VAL_ 591 EPS_TorqueAssistMode 0 "Normal" 1 "light" 2 "heavy" 3 "unknow" ;
VAL_ 591 EPS_IACC_abortreason 0 "NO_DRIVING_INTERUPTION" 1 "DRIVER_RECOVERY(Over ride)" 2 "VEHICLE_SPEED ERROR" 3 "REQUEST ERROR" 4 "DAE_THERMAL_SECURITY" 5 "OTHER_DEFAULT" 6 "ADAS message ErrorCD5690x6=Reserved" 7 "Reserved" ;
VAL_ 651 LCM_LASSwitch 0 "Not Push " 1 "Push " 2 "Reserved " 3 "Fault" ;
VAL_ 651 BCM_TurnIndicatorLeft 0 "OFF" 1 "ON" 2 "Not used" 3 "Error" ;
VAL_ 651 BCM_TurnIndicatorRight 0 "OFF" 1 "ON" 2 "Not used" 3 "Error" ;
VAL_ 651 BCM_emergencylightstatus 0 "OFF" 1 "ON" 2 "Not used" 3 "Error" ;
VAL_ 651 BCM_DriverDoorStatus 0 "Close" 1 "Open" ;
VAL_ 651 BCM_LowBeamStatus 0 "OFF" 1 "ON" 2 "Not used" 3 "Reserved" ;
VAL_ 651 BCM_HighBeamStatus 0 "OFF" 1 "ON" 2 "Not used" 3 "Reserved" ;
VAL_ 651 BCM_TurnLightSwitchSts 0 "Not Actived" 1 "Left Actived" 2 "Right Actived" 3 "Invalid" ;
VAL_ 721 BCM_TrunkDoorStatus 0 "Close" 1 "Open" ;
VAL_ 721 BCM_RightRearDoorStatus 0 "Close" 1 "Open" ;
VAL_ 721 BCM_PassengerDoorStatus 0 "Close" 1 "Open" ;
VAL_ 943 HU_RampDistance 0 " 0~3000m" 301 "reserved" 1022 "Out of Range" 1023 "unknown" ;
VAL_ 943 HU_NavSpeedLimitType 0 "Unknown" 1 "Speed-Limit Sign" 2 "Road Camera" 3 "Interval Velocity" ;
VAL_ 943 HU_CurveDistance 0 " 0~600m" 61 "Out of Range" 62 "reserved" 63 "unknown" ;
VAL_ 943 HU_EnterCurveInfo 0 " unknown" 1 "" 2 "" 3 "" ;
VAL_ 943 HU_NavCurrentRoadType 0 "Road Type Unknown: Small road, Walking Street" 1 "Road Type Class 1: Secondary Roads" 2 "Road Type Class 2: Mainly Road in City" 3 "Road Type Class 3: Mainly Road in City, Normal Province Road, Mainly street" 4 "Road Type Class 4: Province Road, Mainly Road " 5 "Road Type Class 5: Highway, National Road, Speed road" 6 "Reserved 2.ADAS: 0x0=" 1 "" 2 "" 3 "" 4 "" 5 "" 6 "" 7 "" ;
VAL_ 943 HU_EnterRampInfo 0 "Unknown" 1 "" 2 "" 3 "" ;
VAL_ 943 HU_RampInfo 0 "Unknown" 1 "" 2 "" 3 "" ;
VAL_ 943 HU_NavStatus 0 "Normal" 1 "Error" ;
VAL_ 943 HU_NavSpeedLimitUnits 3 "reserved" 2 "unit mph" 1 "unit kph" 0 "unknown." ;
VAL_ 943 HU_NavSpeedLimitStatus 3 "reserved" 2 "reserved" 1 "invalid" 0 "valid" ;
VAL_ 943 HU_NavSpeedLimit 0 "Unlimited" 1 "SL 5" 2 "SL 10" 32 "SL 160" 254 "Unknown" 255 "Invalid" ;
VAL_ 947 BCM_RearFoglampStatus 0 "OFF" 1 "ON" 2 "Not used" 3 "Error" ;
VAL_ 957 HU_ELKEnable 0 "Inactive" 1 "OFF" 2 "ON" 3 "Reserved" ;
VAL_ 957 HU_TLAEnable 0 "Inactive" 1 "OFF" 2 "ON" 3 "Reserved" ;
VAL_ 964 HU_MapMatchStatus 0 "Successl" 1 "Fail" 2 "" 3 "" ;
VAL_ 964 HU_MapDataUpdateStatus 0 "" 1 "1" 2 "3" 3 "6" 4 "1" 5 " reserved" 7 "Invalid" ;
VAL_ 964 HU_SlopeGradient_300m 1023 " unknown" ;
VAL_ 964 HU_RoadCurvature_600m 0 " -0.16192 ~ -0.00001" 8191 " 00" 512 " 0.00001 ~ 0.16192" 5631 " unknown" ;
VAL_ 964 HU_RoadCurvature_400m 0 " -0.16192 ~ -0.00001" 8191 " 00" 512 " 0.00001 ~ 0.16192" 5375 " unknown" ;
VAL_ 964 HU_RoadCurvature_300m 0 " -0.16192 ~ -0.00001" 8191 " 00" 512 " 0.00001 ~ 0.16192" 5119 " unknown" ;
VAL_ 964 HU_RoadCurvature_100m 0 " -0.16192 ~ -0.00001" 8191 " 00" 512 " 0.00001 ~ 0.16192" 4863 " unknown" ;
VAL_ 964 HU_RoadCurvature_90m 0 " -0.16192 ~ -0.00001" 8191 " 00" 512 " 0.00001 ~ 0.16192" 4607 " unknown" ;
VAL_ 964 HU_RoadCurvature_80m 0 " -0.16192 ~ -0.00001" 8191 " 00" 512 " 0.00001 ~ 0.16192" 4351 " unknown" ;
VAL_ 964 HU_RoadCurvature_70m 0 " -0.16192 ~ -0.00001" 8191 " 00" 512 " 0.00001 ~ 0.16192" 2559 " unknown" ;
VAL_ 964 HU_RoadCurvature_60m 0 " -0.16192 ~ -0.00001" 8191 " 00" 512 " 0.00001 ~ 0.16192" 2303 " unknown" ;
VAL_ 964 HU_RoadCurvature_50m 0 " -0.16192 ~ -0.00001" 8191 " 00" 512 " 0.00001 ~ 0.16192" 2047 " unknown" ;
VAL_ 964 HU_RoadCurvature_40m 0 " -0.16192 ~ -0.00001" 8191 " 00" 512 " 0.00001 ~ 0.16192" 1791 " unknown" ;
VAL_ 964 HU_RoadCurvature_30m 0 " -0.16192 ~ -0.00001" 8191 " 00" 512 " 0.00001 ~ 0.16192" 1535 " unknown" ;
VAL_ 964 HU_RoadCurvature_20m 0 " -0.16192 ~ -0.00001" 8191 " 00" 512 " 0.00001 ~ 0.16192" 1279 " unknown" ;
VAL_ 964 HU_RoadCurvature_10m 0 " -0.16192 ~ -0.00001" 8191 " 00" 512 " 0.00001 ~ 0.16192" 1023 " unknown" ;
VAL_ 964 HU_Road_TrafficFlow 0 "unknown" 1 "" 2 "" 3 " 0x4=0x5=,0x6=reserved.0x7=invalid" ;
VAL_ 964 HU_Lane_Changtype 0 "NO change0x1=Merge" 2 "Separate 0x3=invalid" ;
VAL_ 964 HU_To_NumchangeOfLanes_Dist 0 " 0~600m" 61 "Out of Range" 62 "reserved" 63 "unknown" ;
VAL_ 964 HU_To_Branch_Dis 0 " 0~600m" 61 "Out of Range" 62 "reserved" 63 "unknown" ;
VAL_ 964 HU_BranchInfo 0 "unknown" 1 "" 2 " 0x3=" ;
VAL_ 964 HU_To_TrafficAccident_Dis 0 " 0~600m" 61 "Out of Range" 62 "reserved" 63 "unknown" ;
VAL_ 964 HU_TrafficAccident_Info 0 "" 1 " 0x2= 0x3=invalid" ;
VAL_ 964 HU_To_Construction_Dis 0 " 0~600m" 61 "Out of Range" 62 "reserved" 63 "unknown" ;
VAL_ 964 HU_Construction_Info 0 "" 1 "" 2 " 0x3=invalid" ;
VAL_ 964 HU_TollDis 0 " 0~600m" 61 "Out of Range" 62 "reserved" 63 "unknown" ;
VAL_ 964 HU_TollInfo 0 "= 0x1= 0x2= 0x3=invalid" ;
VAL_ 964 HU_FallingRockDi 0 " 0~600m" 61 "Out of Range" 62 "reserved" 63 "unknown" ;
VAL_ 964 HU_FallingRockInfo 0 "= 0x1= 0x2= 0x3=invalid" ;
VAL_ 964 HU_LaneCnt 0 "unknown,0x1-0x5=0x6=6,,0x7=" ;
VAL_ 964 HU_ForwardRoadType 0 "Road Type Unknown: Small road, Walking Street" 1 "Road Type Class 1: Secondary Roads" 2 "Road Type Class 2: Mainly Road in City" 3 "Road Type Class 3: Mainly Road in City, Normal Province Road, Mainly street" 4 "Road Type Class 4: Province Road, Mainly Road " 5 "Road Type Class 5: Highway, National Road, Speed road" 6 "Reserved 2.ADAS: 0x0=" 1 "" 2 "" 3 "" 4 "" 5 "" 6 "" 7 "" ;
VAL_ 964 HU_RampSide 0 "Unknown" 1 "" 2 "" 3 "" ;
VAL_ 964 HU_NavGuiganceStatus 0 "" 1 "" 2 "Reserved" 3 "Reserved" ;
VAL_ 964 HU_SlopeDistance 0 " 0~600m" 61 "Out of Range" 62 "reserved" 63 "unknown" ;
VAL_ 964 HU_Byroad 0 "unknown" 1 "" 2 "" 3 "reserved" ;
VAL_ 964 HU_TunnelLength 0 " 0~600m" 61 "Out of Range" 62 "reserved" 63 "unknown" ;
VAL_ 964 HU_RoadCurvatureFar 0 " -0.16192 ~ -0.00001" 8191 " 00" 512 " 0.00001 ~ 0.16192" 1023 " unknown" ;
VAL_ 964 HU_TunnelDistance 0 " 0~600m" 61 "Out of Range" 62 "reserved" 63 "unknown" ;
VAL_ 964 HU_RoadCurvature 0 " -0.16192 ~ -0.00001" 8191 " 00" 512 " 0.00001 ~ 0.16192" 1023 " unknown" ;
VAL_ 964 HU_EnterSlopeInfo 0 "unknown" 1 "" 2 "" 3 "" ;
VAL_ 964 HU_EnterTunnelInfo 0 " unknown" 1 "" 2 "" 3 "" ;
VAL_ 1021 BCM_PowerManageLevel 0 "Valid; 0x1 =Level1; 0x2 = Level2;  0x3 = Level3;;0x4= Level4;0x5-0x6=Reserve;0x7 =Invalid" ;
VAL_ 1023 BCM_RightLowBeamError 0 "" 1 "" ;
VAL_ 1023 BCM_LeftLowBeamError 0 "" 1 "" ;
VAL_ 1023 BCM_AutoHeadlightSts 0 "Not Actived" 1 "Actived" ;
VAL_ 1023 BCM_FrontFoglampStatus 0 "OFF" 1 "ON" 2 "Not used" 3 "Reserved" ;
VAL_ 652 GW_MFS_IACCenable_switch_signal 0 "" 1 "" 2 "" 3 "Error" ;
VAL_ 800 GW_ResetReq 0 "" ;
VAL_ 922 LAS_ResetSts 0 "Valid; 0x1 =GW;0x2 =;  0x3=;0x4~0x6=Reserve;0x7 =Invalid;" ;
VAL_ 922 LAS_TSRRightLaneStatus 0 " off" 1 " fusion mode" 2 " vision only mode" 3 " navigation only mode" 4 " reserved" 5 " reserved" 6 " reserved" 7 " Invalid" ;
VAL_ 922 LAS_TSRLeftLaneStatus 0 " off" 1 " fusion mode" 2 " vision only mode" 3 " navigation only mode" 4 " reserved" 5 " reserved" 6 " reserved" 7 " Invalid" ;
VAL_ 922 LAS_TSRRightLaneSpdLimit 0 "no speed limit detected" 1 "SL5" 2 "SL10" 3 "SL15" 4 "SL20" 5 "SL25" 6 "SL30" 7 "SL35" 8 "SL40" 9 "SL45" 10 "SL50" 11 "SL55" 12 "SL60" 13 "SL65" 14 "SL70" 15 "SL75" 16 "SL80" 17 "SL85" 18 "SL90" 19 "SL95" 20 "SL100" 21 "SL105" 22 "SL110" 23 "SL115" 24 "SL120" 25 "SL125" 26 "SL130" 27 "SL135" 28 "SL140" 29 "SL145" 30 "SL150" 31 "SL155" 32 "SL160" 33 " Reserved" 254 " Unlimited" 255 " SLEND" ;
VAL_ 922 LAS_TSRLeftLaneSpdLimit 0 "no speed limit detected" 1 "SL5" 2 "SL10" 3 "SL15" 4 "SL20" 5 "SL25" 6 "SL30" 7 "SL35" 8 "SL40" 9 "SL45" 10 "SL50" 11 "SL55" 12 "SL60" 13 "SL65" 14 "SL70" 15 "SL75" 16 "SL80" 17 "SL85" 18 "SL90" 19 "SL95" 20 "SL100" 21 "SL105" 22 "SL110" 23 "SL115" 24 "SL120" 25 "SL125" 26 "SL130" 27 "SL135" 28 "SL140" 29 "SL145" 30 "SL150" 31 "SL155" 32 "SL160" 33 " Reserved" 254 " Unlimited" 255 " SLEND" ;
VAL_ 922 LAS_TLAStopLine_HostLane 0 "0-250m" 251 "Reserved" 255 "Out of Range" ;
VAL_ 922 LAS_TLADistance_HostLane 0 "0-250m" 251 "Reserved" 255 "Out of Range" ;
VAL_ 922 LAS_TLACountDownTime_HostLane 0 "no display" 1 "1-120s" 121 "reserved" 127 "out of range" ;
VAL_ 922 LAS_TSRMandatorySign 0 "no display" 1 "()" 2 "" 3 "" 4 "" 5 "" 6 "" 7 "reserved" ;
VAL_ 922 LAS_TSRWarningSign 0 "no display" 1 "" 2 "" 3 "" 4 "" 5 "" 6 "" 7 "" 8 "" 9 "reserved" ;
VAL_ 922 LAS_TSRProhibitionSign 0 "no display" 1 "" 2 "" 3 "" 4 "" 5 "" 6 "" 7 "" 8 "" 9 "" 10 "" 11 "" 12 "" 13 "" 14 "" 15 "" 16 "reserved" ;
VAL_ 922 LAS_OverspeedSoundWarningEnSt 0 "Off" 1 "On" ;
VAL_ 922 LAS_TSREnable 0 "off" 1 "on" ;
VAL_ 922 LAS_HMAEnableStatus 0 "off" 1 "on" ;
VAL_ 922 LAS_HMALightDistribution 0 " High beam not recommended" 1 " High beam recommended" ;
VAL_ 922 LAS_HMAStatus 0 " Off" 1 " Standby" 2 " Active" 3 " Failure" ;
VAL_ 922 LAS_TSRHostSpdLimitUnits 0 "no display" 1 "unit kph" 2 "unit mph" 3 "reserved" ;
VAL_ 922 LAS_TSRHostSpdLimit 0 "no speed limit detected" 1 "SL5" 2 "SL10" 3 "SL15" 4 "SL20" 5 "SL25" 6 "SL30" 7 "SL35" 8 "SL40" 9 "SL45" 10 "SL50" 11 "SL55" 12 "SL60" 13 "SL65" 14 "SL70" 15 "SL75" 16 "SL80" 17 "SL85" 18 "SL90" 19 "SL95" 20 "SL100" 21 "SL105" 22 "SL110" 23 "SL115" 24 "SL120" 25 "SL125" 26 "SL130" 27 "SL135" 28 "SL140" 29 "SL145" 30 "SL150" 31 "SL155" 32 "SL160" 33 " Reserved" 254 " Unlimited" 255 " SLEND" ;
VAL_ 922 LAS_TSRStatus 0 " off" 1 " fusion mode" 2 " vision only mode" 3 " navigation only mode" 4 " reserved" 5 " reserved" 6 " reserved" 7 " Invalid" ;
VAL_ 922 LAS_FrontCameraCalibrationStatus 0 " Calibration is ok" 1 " Calibration In Process" 2 " Calibration never done" 3 "  Calibration Failed" ;
VAL_ 922 LAS_FrontCameraFailureStatus 0 "No Error" 1 "camera blocked" 2 "temporary failure" 3 "permanent failure" ;
VAL_ 922 LAS_OverspeedWarningOffset 0 "" 21 "Reserved" 31 "Invalid." ;
VAL_ 922 LAS_OverspeedWarningEnableStatus 0 "OFF" 1 "ON" ;
VAL_ 922 LAS_OverspeedSoundWarning 0 " No Warning" 1 " Warning" ;
VAL_ 922 LAS_OverspeedVisualWarning 0 " No Warning" 1 " Warning" ;
VAL_ 922 LAS_TLAArrowDirection_RightLane 0 "no display" 1 "Forward" 2 "Left" 3 " Forward +Left" 4 "Right" 5 " Forward +Right" 6 "Right+Left" 7 "Left+ Forward +Right" ;
VAL_ 922 LAS_TLAObjectType_RightLane 0 "no display" 1 "Round" 2 "Arrow" 3 "Turn Round" 4 "X-type" 5 "Arrow+Trun 0x6-0x7=reserved" ;
VAL_ 922 LAS_TLAObjectStatus_RightLane 0 "no display" 1 "Lighting" 2 "Flashing" 3 " Disappear" ;
VAL_ 922 LAS_TLAObjectColour_RightLane 0 "no display" 1 "Red" 2 "Yellow" 3 "Green" ;
VAL_ 922 LAS_TLAObjectDetection_RightLane 0 "Not Detected" 1 "Detected" ;
VAL_ 922 LAS_TLAArrowDirection_LeftLane 0 "no display" 1 "Forward" 2 "Left" 3 " Forward +Left" 4 "Right" 5 " Forward +Right" 6 "Right+Left" 7 "Left+ Forward +Right" ;
VAL_ 922 LAS_TLAObjectType_LeftLane 0 "no display" 1 "Round" 2 "Arrow" 3 "Turn Round" 4 "X-type" 5 "Arrow+Trun 0x6-0x7=reserved" ;
VAL_ 922 LAS_TLAObjectStatus_LeftLane 0 "no display" 1 "Lighting" 2 "Flashing" 3 " Disappear" ;
VAL_ 922 LAS_TLAObjectColour_LeftLane 0 "no display" 1 "Red" 2 "Yellow" 3 "Green" ;
VAL_ 922 LAS_TLAObjectDetection_LeftLane 0 "Not Detected" 1 "Detected" ;
VAL_ 922 LAS_TLAArrowDirection_HostLane 0 "no display" 1 "Forward" 2 "Left" 3 " Forward +Left" 4 "Right" 5 " Forward +Right" 6 "Right+Left" 7 "Left+ Forward +Right" ;
VAL_ 922 LAS_TLAObjectStatus_HostLane 0 "no display" 1 "Lighting" 2 "Flashing" 3 " Disappear" ;
VAL_ 922 LAS_TLAObjectType_HostLane 0 "no display" 1 "Round" 2 "Arrow" 3 "Turn Round" 4 "X-type" 5 "Arrow+Trun" 6 "reserved" ;
VAL_ 922 LAS_TLAObjectColour_HostLane 0 "no display" 1 "Red" 2 "Yellow" 3 "Green" ;
VAL_ 922 LAS_TLAObjectDetection_HostLane 0 "Not Detected" 1 "Detected" ;
VAL_ 922 LAS_TLAWarninglevel 0 " no warning" 1 " warning level 1" 2 " warning level 2" 3 " warning level 3." ;
VAL_ 922 LAS_TLAStatus 0 "OFF" 1 "Standby" 2 "Active" 3 "Failure" ;
VAL_ 922 LAS_TLAEnable 0 "OFF" 1 "ON" ;
VAL_ 1000 BCM_SOF_Q_STATE 0 "deviation > 15%" 1 "deviation <15%" 2 "deviation < 10%" 3 "invalid" ;
VAL_ 1000 BCM_SOF_Q 255 "Invalid" ;
VAL_ 999 BCM_Status_Temp 0 "No error" 1 "not used" 2 "HW defect (ADC defect)" 3 "LIN saturation (no HW  defect)" ;
VAL_ 999 BCM_T_BATT 146 "reserved" 255 "Invalid" ;
VAL_ 583 APA_APAOnOff 0 "OFF" 1 "ON" ;
VAL_ 738 RLR_ElkOBJ2_Measured 0 "unknown" 1 "Measured" 2 "Predicted" 3 "Reserved" ;
VAL_ 738 RLR_ElkOBJ2_Location 0 "unknown" 1 "Left Lane" 2 "Right  Lane" 3 "Ego Lane" ;
VAL_ 738 RLR_ElkOBJ2_Type 0 "Not Detected" 1 "car" 2 "truck" 3 "bicycle/motorbike" 4 "pedestrian" 5 "general" 6 "animal" 7 "uncertain" ;
VAL_ 738 RLR_ElkOBJ1_Measured 0 "unknown" 1 "Measured" 2 "Predicted" 3 "Reserved" ;
VAL_ 738 RLR_ElkOBJ1_Location 0 "unknown" 1 "Left Lane" 2 "Right  Lane" 3 "Ego Lane" ;
VAL_ 738 RLR_ElkOBJ1_Type 0 "Not Detected" 1 "car" 2 "truck" 3 "bicycle/motorbike" 4 "pedestrian" 5 "general" 6 "animal" 7 "uncertain" ;
VAL_ 739 RLR_ElkOBJ4_Measured 0 "unknown" 1 "Measured" 2 "Predicted" 3 "Reserved" ;
VAL_ 739 RLR_ElkOBJ4_Location 0 "unknown" 1 "Left Lane" 2 "Right  Lane" 3 "Ego Lane" ;
VAL_ 739 RLR_ElkOBJ4_Type 0 "Not Detected" 1 "car" 2 "truck" 3 "bicycle/motorbike" 4 "pedestrian" 5 "general" 6 "animal" 7 "uncertain" ;
VAL_ 739 RLR_ElkOBJ3_Measured 0 "unknown" 1 "Measured" 2 "Predicted" 3 "Reserved" ;
VAL_ 739 RLR_ElkOBJ3_Location 0 "unknown" 1 "Left Lane" 2 "Right  Lane" 3 "Ego Lane" ;
VAL_ 739 RLR_ElkOBJ3_Type 0 "Not Detected" 1 "car" 2 "truck" 3 "bicycle/motorbike" 4 "pedestrian" 5 "general" 6 "animal" 7 "uncertain" ;
